VERSION "HINBNNNYYNNNYYNNNNNNNNNNNNYNNNYYYNNYNNNNNN/4//%%/4/'%**4NNN///"

NS_ :

BS_:

BU_: VirtualNMTMaster Master LadderDrive ControlPanel SupportFront SupportRear TTGateway

BO_ 1410 SSDO_002: 8 TTGateway
 SG_ requested_engine_speed_minimum_v m3 : 32|16@1+ (1,0) [0|65535] "" Vector__XXX
 SG_ requested_engine_speed_maximum_v m2 : 32|16@1+ (1,0) [0|65535] "" Vector__XXX
 SG_ requested_engine_speed_value_614 m1 : 32|16@1+ (1,0) [0|65535] "" Vector__XXX
 SG_ requested_engine_speed_number_of m0 : 32|8@1+ (1,0) [0|255] "" Vector__XXX
 SG_ SubIndex_614A m24906M : 24|8@1+ (1,0) [0|3] "" Vector__XXX
 SG_ requested_engine_speed_lowe_0001 m3 : 32|16@1+ (1,0) [0|65535] "" Vector__XXX
 SG_ requested_engine_speed_lowe_0002 m2 : 32|16@1+ (1,0) [0|65535] "" Vector__XXX
 SG_ requested_engine_speed_lowe_0003 m1 : 32|16@1+ (1,0) [0|65535] "" Vector__XXX
 SG_ requested_engine_speed_lowe_0004 m0 : 32|8@1+ (1,0) [0|255] "" Vector__XXX
 SG_ SubIndex_6142 m24898M : 24|8@1+ (1,0) [0|3] "" Vector__XXX
 SG_ requested_engine_speed_uppe_0001 m3 : 32|16@1+ (1,0) [0|65535] "" Vector__XXX
 SG_ requested_engine_speed_uppe_0002 m2 : 32|16@1+ (1,0) [0|65535] "" Vector__XXX
 SG_ requested_engine_speed_uppe_0003 m1 : 32|16@1+ (1,0) [0|65535] "" Vector__XXX
 SG_ requested_engine_speed_uppe_0004 m0 : 32|8@1+ (1,0) [0|255] "" Vector__XXX
 SG_ SubIndex_6140 m24896M : 24|8@1+ (1,0) [0|3] "" Vector__XXX
 SG_ engine_stop_switch_Bit_1_613F_01 m1 : 32|8@1+ (1,0) [0|255] "" Vector__XXX
 SG_ engine_stop_switch_Number_of_ent m0 : 32|8@1+ (1,0) [0|255] "" Vector__XXX
 SG_ SubIndex_613F m24895M : 24|8@1+ (1,0) [0|1] "" Vector__XXX
 SG_ engine_start_switch_Bit_1_613E_0 m1 : 32|8@1+ (1,0) [0|255] "" Vector__XXX
 SG_ engine_start_switch_Number_of_en m0 : 32|8@1+ (1,0) [0|255] "" Vector__XXX
 SG_ SubIndex_613E m24894M : 24|8@1+ (1,0) [0|1] "" Vector__XXX
 SG_ first_clutch_dependent_PTO__0001 m1 : 32|8@1+ (1,0) [0|255] "" Vector__XXX
 SG_ first_clutch_dependent_PTO__0002 m0 : 32|8@1+ (1,0) [0|255] "" Vector__XXX
 SG_ SubIndex_6136 m24886M : 24|8@1+ (1,0) [0|1] "" Vector__XXX
 SG_ first_engine_mounted_PTO_fe_0001 m1 : 32|8@1+ (1,0) [0|255] "" Vector__XXX
 SG_ first_engine_mounted_PTO_fe_0002 m0 : 32|8@1+ (1,0) [0|255] "" Vector__XXX
 SG_ SubIndex_6131 m24881M : 24|8@1+ (1,0) [0|1] "" Vector__XXX
 SG_ engine_speed_minimum_value_range m3 : 32|16@1+ (1,0) [0|65535] "" Vector__XXX
 SG_ engine_speed_maximum_value_range m2 : 32|16@1+ (1,0) [0|65535] "" Vector__XXX
 SG_ EngineSpeed_6113_01 m1 : 32|16@1+ (1,0) [0|65535] "" Vector__XXX
 SG_ NrOfObjects_6113_00 m0 : 32|8@1+ (1,0) [0|255] "" Vector__XXX
 SG_ SubIndex_6113 m24851M : 24|8@1+ (1,0) [0|3] "" Vector__XXX
 SG_ current_gear_minimum_value_range m3 : 32|8@1- (1,0) [-128|127] "" Vector__XXX
 SG_ current_gear_maximum_value_range m2 : 32|8@1- (1,0) [-128|127] "" Vector__XXX
 SG_ CurrentGearValue_610C_01 m1 : 32|8@1- (1,0) [-128|127] "" Vector__XXX
 SG_ NrOfObjects_610C_00 m0 : 32|8@1+ (1,0) [0|255] "" Vector__XXX
 SG_ SubIndex_610C m24844M : 24|8@1+ (1,0) [0|3] "" Vector__XXX
 SG_ wheel_based_vehicle_speed_minimu m3 : 32|16@1+ (1,0) [0|65535] "" Vector__XXX
 SG_ wheel_based_vehicle_speed_maximu m2 : 32|16@1+ (1,0) [0|65535] "" Vector__XXX
 SG_ wheel_based_vehicle_speed_v_0001 m1 : 32|16@1+ (1,0) [0|65535] "" Vector__XXX
 SG_ wheel_based_vehicle_speed_number m0 : 32|8@1+ (1,0) [0|255] "" Vector__XXX
 SG_ SubIndex_6006 m24582M : 24|8@1+ (1,0) [0|3] "" Vector__XXX
 SG_ park_brake_demand_value_minimum_ m3 : 32|8@1+ (1,0) [0|255] "" Vector__XXX
 SG_ park_brake_demand_value_maximum_ m2 : 32|8@1+ (1,0) [0|255] "" Vector__XXX
 SG_ ParkBrakeDemandValue_6000_01 m1 : 32|8@1+ (1,0) [0|255] "" Vector__XXX
 SG_ NrOfObjects_6000_00 m0 : 32|8@1+ (1,0) [0|255] "" Vector__XXX
 SG_ SubIndex_6000 m24576M : 24|8@1+ (1,0) [0|3] "" Vector__XXX
 SG_ NrOfMappedObjects_1A02_00 m0 : 32|8@1+ (1,0) [0|64] "" Vector__XXX
 SG_ SubIndex_1A02 m6658M : 24|8@1+ (1,0) [0|0] "" Vector__XXX
 SG_ NrOfMappedObjects_1A01_00 m0 : 32|8@1+ (1,0) [0|64] "" Vector__XXX
 SG_ SubIndex_1A01 m6657M : 24|8@1+ (1,0) [0|0] "" Vector__XXX
 SG_ mappedObj5_1A00_05 m5 : 32|32@1+ (1,0) [0|4294967295] "" Vector__XXX
 SG_ mappedObj4_1A00_04 m4 : 32|32@1+ (1,0) [0|4294967295] "" Vector__XXX
 SG_ mappedObj3_1A00_03 m3 : 32|32@1+ (1,0) [0|4294967295] "" Vector__XXX
 SG_ mappedObj2_1A00_02 m2 : 32|32@1+ (1,0) [0|4294967295] "" Vector__XXX
 SG_ mappedObj1_1A00_01 m1 : 32|32@1+ (1,0) [0|4294967295] "" Vector__XXX
 SG_ NrOfMappedObjects_1A00_00 m0 : 32|8@1+ (1,0) [0|64] "" Vector__XXX
 SG_ SubIndex_1A00 m6656M : 24|8@1+ (1,0) [0|5] "" Vector__XXX
 SG_ EventTimer_1802_05 m5 : 32|16@1+ (1,0) [0|65535] "" Vector__XXX
 SG_ TransmissionType_1802_02 m2 : 32|8@1+ (1,0) [0|255] "" Vector__XXX
 SG_ COB_ID_1802_01 m1 : 32|32@1+ (1,0) [1|4294967295] "" Vector__XXX
 SG_ NrOfEntries_1802_00 m0 : 32|8@1+ (1,0) [2|5] "" Vector__XXX
 SG_ SubIndex_1802 m6146M : 24|8@1+ (1,0) [0|5] "" Vector__XXX
 SG_ EventTimer_1801_05 m5 : 32|16@1+ (1,0) [0|65535] "" Vector__XXX
 SG_ TransmissionType_1801_02 m2 : 32|8@1+ (1,0) [0|255] "" Vector__XXX
 SG_ COB_ID_1801_01 m1 : 32|32@1+ (1,0) [1|4294967295] "" Vector__XXX
 SG_ NrOfEntries_1801_00 m0 : 32|8@1+ (1,0) [2|5] "" Vector__XXX
 SG_ SubIndex_1801 m6145M : 24|8@1+ (1,0) [0|5] "" Vector__XXX
 SG_ EventTimer_1800_05 m5 : 32|16@1+ (1,0) [0|65535] "" Vector__XXX
 SG_ TransmissionType_1800_02 m2 : 32|8@1+ (1,0) [0|255] "" Vector__XXX
 SG_ COB_ID_1800_01 m1 : 32|32@1+ (1,0) [1|4294967295] "" Vector__XXX
 SG_ NrOfEntries_1800_00 m0 : 32|8@1+ (1,0) [2|5] "" Vector__XXX
 SG_ SubIndex_1800 m6144M : 24|8@1+ (1,0) [0|5] "" Vector__XXX
 SG_ NrOfMappedObjects_1602_00 m0 : 32|8@1+ (1,0) [0|64] "" Vector__XXX
 SG_ SubIndex_1602 m5634M : 24|8@1+ (1,0) [0|0] "" Vector__XXX
 SG_ mappedObj1_1601_01 m1 : 32|32@1+ (1,0) [0|4294967295] "" Vector__XXX
 SG_ NrOfMappedObjects_1601_00 m0 : 32|8@1+ (1,0) [0|64] "" Vector__XXX
 SG_ SubIndex_1601 m5633M : 24|8@1+ (1,0) [0|1] "" Vector__XXX
 SG_ mappedObj5_1600_05 m5 : 32|32@1+ (1,0) [0|4294967295] "" Vector__XXX
 SG_ mappedObj4_1600_04 m4 : 32|32@1+ (1,0) [0|4294967295] "" Vector__XXX
 SG_ mappedObj3_1600_03 m3 : 32|32@1+ (1,0) [0|4294967295] "" Vector__XXX
 SG_ mappedObj2_1600_02 m2 : 32|32@1+ (1,0) [0|4294967295] "" Vector__XXX
 SG_ mappedObj1_1600_01 m1 : 32|32@1+ (1,0) [0|4294967295] "" Vector__XXX
 SG_ NrOfMappedObjects_1600_00 m0 : 32|8@1+ (1,0) [0|64] "" Vector__XXX
 SG_ SubIndex_1600 m5632M : 24|8@1+ (1,0) [0|5] "" Vector__XXX
 SG_ TransmissionType_1402_02 m2 : 32|8@1+ (1,0) [0|255] "" Vector__XXX
 SG_ COB_ID_1402_01 m1 : 32|32@1+ (1,0) [1|4294967295] "" Vector__XXX
 SG_ NrOfEntries_1402_00 m0 : 32|8@1+ (1,0) [2|5] "" Vector__XXX
 SG_ SubIndex_1402 m5122M : 24|8@1+ (1,0) [0|2] "" Vector__XXX
 SG_ TransmissionType_1401_02 m2 : 32|8@1+ (1,0) [0|255] "" Vector__XXX
 SG_ COB_ID_1401_01 m1 : 32|32@1+ (1,0) [1|4294967295] "" Vector__XXX
 SG_ NrOfEntries_1401_00 m0 : 32|8@1+ (1,0) [2|5] "" Vector__XXX
 SG_ SubIndex_1401 m5121M : 24|8@1+ (1,0) [0|2] "" Vector__XXX
 SG_ TransmissionType_1400_02 m2 : 32|8@1+ (1,0) [0|255] "" Vector__XXX
 SG_ COB_ID_1400_01 m1 : 32|32@1+ (1,0) [1|4294967295] "" Vector__XXX
 SG_ NrOfEntries_1400_00 m0 : 32|8@1+ (1,0) [2|5] "" Vector__XXX
 SG_ SubIndex_1400 m5120M : 24|8@1+ (1,0) [0|2] "" Vector__XXX
 SG_ Vendor_Id_1018_01 m1 : 32|32@1+ (1,0) [0|4294967295] "" Vector__XXX
 SG_ NrOfElements_1018_00 m0 : 32|8@1+ (1,0) [1|4] "" Vector__XXX
 SG_ SubIndex_1018 m4120M : 24|8@1+ (1,0) [0|1] "" Vector__XXX
 SG_ Sync_Window_Length_1007 m0 : 32|32@1+ (1,0) [0|4294967295] "" Vector__XXX
 SG_ SubIndex_1007 m4103M : 24|8@1+ (1,0) [0|0] "" Vector__XXX
 SG_ Communication_Cycle_Period_1006 m0 : 32|32@1+ (1,0) [0|4294967295] "" Vector__XXX
 SG_ SubIndex_1006 m4102M : 24|8@1+ (1,0) [0|0] "" Vector__XXX
 SG_ COB_ID_SYNC_1005 m0 : 32|32@1+ (1,0) [1|4294967295] "" Vector__XXX
 SG_ SubIndex_1005 m4101M : 24|8@1+ (1,0) [0|0] "" Vector__XXX
 SG_ ErrorRegister_1001 m0 : 32|8@1+ (1,0) [0|255] "" Vector__XXX
 SG_ SubIndex_1001 m4097M : 24|8@1+ (1,0) [0|0] "" Vector__XXX
 SG_ Device_Type_1000 m0 : 32|32@1+ (1,0) [0|4294967295] "" Vector__XXX
 SG_ SubIndex_1000 m4096M : 24|8@1+ (1,0) [0|0] "" Vector__XXX
 SG_ Index m1M : 8|16@1+ (1,0) [4096|24906] "" Vector__XXX
 SG_ TransferType m1M : 1|1@1+ (1,0) [0|1] "" Vector__XXX
 SG_ NotUsedBytes m1 : 2|2@1+ (1,0) [0|3] "" Vector__XXX
 SG_ SizeIndicator m1 : 0|1@1+ (1,0) [0|1] "" Vector__XXX
 SG_ SCS M : 5|3@1+ (1,0) [0|6] "" Vector__XXX

BO_ 1538 CSDO_002: 8 Vector__XXX
 SG_ requested_engine_speed_mini_0000 m3 : 32|16@1+ (1,0) [0|65535] ""  TTGateway
 SG_ requested_engine_speed_maxi_0000 m2 : 32|16@1+ (1,0) [0|65535] ""  TTGateway
 SG_ requested_engine_speed_valu_0001 m1 : 32|16@1+ (1,0) [0|65535] ""  TTGateway
 SG_ requested_engine_speed_numb_0000 m0 : 32|8@1+ (1,0) [0|255] ""  TTGateway
 SG_ SubIndex_614A m24906M : 24|8@1+ (1,0) [0|3] ""  TTGateway
 SG_ requested_engine_speed_lowe_0005 m3 : 32|16@1+ (1,0) [0|65535] ""  TTGateway
 SG_ requested_engine_speed_lowe_0006 m2 : 32|16@1+ (1,0) [0|65535] ""  TTGateway
 SG_ requested_engine_speed_lowe_0007 m1 : 32|16@1+ (1,0) [0|65535] ""  TTGateway
 SG_ requested_engine_speed_lowe_0008 m0 : 32|8@1+ (1,0) [0|255] ""  TTGateway
 SG_ SubIndex_6142 m24898M : 24|8@1+ (1,0) [0|3] ""  TTGateway
 SG_ requested_engine_speed_uppe_0005 m3 : 32|16@1+ (1,0) [0|65535] ""  TTGateway
 SG_ requested_engine_speed_uppe_0006 m2 : 32|16@1+ (1,0) [0|65535] ""  TTGateway
 SG_ requested_engine_speed_uppe_0007 m1 : 32|16@1+ (1,0) [0|65535] ""  TTGateway
 SG_ requested_engine_speed_uppe_0008 m0 : 32|8@1+ (1,0) [0|255] ""  TTGateway
 SG_ SubIndex_6140 m24896M : 24|8@1+ (1,0) [0|3] ""  TTGateway
 SG_ engine_stop_switch_Bit_1_613F_01 m1 : 32|8@1+ (1,0) [0|255] ""  TTGateway
 SG_ engine_stop_switch_Number_o_0000 m0 : 32|8@1+ (1,0) [0|255] ""  TTGateway
 SG_ SubIndex_613F m24895M : 24|8@1+ (1,0) [0|1] ""  TTGateway
 SG_ engine_start_switch_Bit_1_6_0000 m1 : 32|8@1+ (1,0) [0|255] ""  TTGateway
 SG_ engine_start_switch_Number__0000 m0 : 32|8@1+ (1,0) [0|255] ""  TTGateway
 SG_ SubIndex_613E m24894M : 24|8@1+ (1,0) [0|1] ""  TTGateway
 SG_ first_clutch_dependent_PTO__0003 m1 : 32|8@1+ (1,0) [0|255] ""  TTGateway
 SG_ first_clutch_dependent_PTO__0004 m0 : 32|8@1+ (1,0) [0|255] ""  TTGateway
 SG_ SubIndex_6136 m24886M : 24|8@1+ (1,0) [0|1] ""  TTGateway
 SG_ first_engine_mounted_PTO_fe_0003 m1 : 32|8@1+ (1,0) [0|255] ""  TTGateway
 SG_ first_engine_mounted_PTO_fe_0004 m0 : 32|8@1+ (1,0) [0|255] ""  TTGateway
 SG_ SubIndex_6131 m24881M : 24|8@1+ (1,0) [0|1] ""  TTGateway
 SG_ engine_speed_minimum_value__0000 m3 : 32|16@1+ (1,0) [0|65535] ""  TTGateway
 SG_ engine_speed_maximum_value__0000 m2 : 32|16@1+ (1,0) [0|65535] ""  TTGateway
 SG_ EngineSpeed_6113_01 m1 : 32|16@1+ (1,0) [0|65535] ""  TTGateway
 SG_ NrOfObjects_6113_00 m0 : 32|8@1+ (1,0) [0|255] ""  TTGateway
 SG_ SubIndex_6113 m24851M : 24|8@1+ (1,0) [0|3] ""  TTGateway
 SG_ current_gear_minimum_value__0000 m3 : 32|8@1- (1,0) [-128|127] ""  TTGateway
 SG_ current_gear_maximum_value__0000 m2 : 32|8@1- (1,0) [-128|127] ""  TTGateway
 SG_ CurrentGearValue_610C_01 m1 : 32|8@1- (1,0) [-128|127] ""  TTGateway
 SG_ NrOfObjects_610C_00 m0 : 32|8@1+ (1,0) [0|255] ""  TTGateway
 SG_ SubIndex_610C m24844M : 24|8@1+ (1,0) [0|3] ""  TTGateway
 SG_ wheel_based_vehicle_speed_m_0000 m3 : 32|16@1+ (1,0) [0|65535] ""  TTGateway
 SG_ wheel_based_vehicle_speed_m_0001 m2 : 32|16@1+ (1,0) [0|65535] ""  TTGateway
 SG_ wheel_based_vehicle_speed_v_0002 m1 : 32|16@1+ (1,0) [0|65535] ""  TTGateway
 SG_ wheel_based_vehicle_speed_n_0000 m0 : 32|8@1+ (1,0) [0|255] ""  TTGateway
 SG_ SubIndex_6006 m24582M : 24|8@1+ (1,0) [0|3] ""  TTGateway
 SG_ park_brake_demand_value_min_0000 m3 : 32|8@1+ (1,0) [0|255] ""  TTGateway
 SG_ park_brake_demand_value_max_0000 m2 : 32|8@1+ (1,0) [0|255] ""  TTGateway
 SG_ ParkBrakeDemandValue_6000_01 m1 : 32|8@1+ (1,0) [0|255] ""  TTGateway
 SG_ NrOfObjects_6000_00 m0 : 32|8@1+ (1,0) [0|255] ""  TTGateway
 SG_ SubIndex_6000 m24576M : 24|8@1+ (1,0) [0|3] ""  TTGateway
 SG_ NrOfMappedObjects_1A02_00 m0 : 32|8@1+ (1,0) [0|64] ""  TTGateway
 SG_ SubIndex_1A02 m6658M : 24|8@1+ (1,0) [0|0] ""  TTGateway
 SG_ NrOfMappedObjects_1A01_00 m0 : 32|8@1+ (1,0) [0|64] ""  TTGateway
 SG_ SubIndex_1A01 m6657M : 24|8@1+ (1,0) [0|0] ""  TTGateway
 SG_ mappedObj5_1A00_05 m5 : 32|32@1+ (1,0) [0|4294967295] ""  TTGateway
 SG_ mappedObj4_1A00_04 m4 : 32|32@1+ (1,0) [0|4294967295] ""  TTGateway
 SG_ mappedObj3_1A00_03 m3 : 32|32@1+ (1,0) [0|4294967295] ""  TTGateway
 SG_ mappedObj2_1A00_02 m2 : 32|32@1+ (1,0) [0|4294967295] ""  TTGateway
 SG_ mappedObj1_1A00_01 m1 : 32|32@1+ (1,0) [0|4294967295] ""  TTGateway
 SG_ NrOfMappedObjects_1A00_00 m0 : 32|8@1+ (1,0) [0|64] ""  TTGateway
 SG_ SubIndex_1A00 m6656M : 24|8@1+ (1,0) [0|5] ""  TTGateway
 SG_ EventTimer_1802_05 m5 : 32|16@1+ (1,0) [0|65535] ""  TTGateway
 SG_ TransmissionType_1802_02 m2 : 32|8@1+ (1,0) [0|255] ""  TTGateway
 SG_ COB_ID_1802_01 m1 : 32|32@1+ (1,0) [1|4294967295] ""  TTGateway
 SG_ NrOfEntries_1802_00 m0 : 32|8@1+ (1,0) [2|5] ""  TTGateway
 SG_ SubIndex_1802 m6146M : 24|8@1+ (1,0) [0|5] ""  TTGateway
 SG_ EventTimer_1801_05 m5 : 32|16@1+ (1,0) [0|65535] ""  TTGateway
 SG_ TransmissionType_1801_02 m2 : 32|8@1+ (1,0) [0|255] ""  TTGateway
 SG_ COB_ID_1801_01 m1 : 32|32@1+ (1,0) [1|4294967295] ""  TTGateway
 SG_ NrOfEntries_1801_00 m0 : 32|8@1+ (1,0) [2|5] ""  TTGateway
 SG_ SubIndex_1801 m6145M : 24|8@1+ (1,0) [0|5] ""  TTGateway
 SG_ EventTimer_1800_05 m5 : 32|16@1+ (1,0) [0|65535] ""  TTGateway
 SG_ TransmissionType_1800_02 m2 : 32|8@1+ (1,0) [0|255] ""  TTGateway
 SG_ COB_ID_1800_01 m1 : 32|32@1+ (1,0) [1|4294967295] ""  TTGateway
 SG_ NrOfEntries_1800_00 m0 : 32|8@1+ (1,0) [2|5] ""  TTGateway
 SG_ SubIndex_1800 m6144M : 24|8@1+ (1,0) [0|5] ""  TTGateway
 SG_ NrOfMappedObjects_1602_00 m0 : 32|8@1+ (1,0) [0|64] ""  TTGateway
 SG_ SubIndex_1602 m5634M : 24|8@1+ (1,0) [0|0] ""  TTGateway
 SG_ mappedObj1_1601_01 m1 : 32|32@1+ (1,0) [0|4294967295] ""  TTGateway
 SG_ NrOfMappedObjects_1601_00 m0 : 32|8@1+ (1,0) [0|64] ""  TTGateway
 SG_ SubIndex_1601 m5633M : 24|8@1+ (1,0) [0|1] ""  TTGateway
 SG_ mappedObj5_1600_05 m5 : 32|32@1+ (1,0) [0|4294967295] ""  TTGateway
 SG_ mappedObj4_1600_04 m4 : 32|32@1+ (1,0) [0|4294967295] ""  TTGateway
 SG_ mappedObj3_1600_03 m3 : 32|32@1+ (1,0) [0|4294967295] ""  TTGateway
 SG_ mappedObj2_1600_02 m2 : 32|32@1+ (1,0) [0|4294967295] ""  TTGateway
 SG_ mappedObj1_1600_01 m1 : 32|32@1+ (1,0) [0|4294967295] ""  TTGateway
 SG_ NrOfMappedObjects_1600_00 m0 : 32|8@1+ (1,0) [0|64] ""  TTGateway
 SG_ SubIndex_1600 m5632M : 24|8@1+ (1,0) [0|5] ""  TTGateway
 SG_ TransmissionType_1402_02 m2 : 32|8@1+ (1,0) [0|255] ""  TTGateway
 SG_ COB_ID_1402_01 m1 : 32|32@1+ (1,0) [1|4294967295] ""  TTGateway
 SG_ NrOfEntries_1402_00 m0 : 32|8@1+ (1,0) [2|5] ""  TTGateway
 SG_ SubIndex_1402 m5122M : 24|8@1+ (1,0) [0|2] ""  TTGateway
 SG_ TransmissionType_1401_02 m2 : 32|8@1+ (1,0) [0|255] ""  TTGateway
 SG_ COB_ID_1401_01 m1 : 32|32@1+ (1,0) [1|4294967295] ""  TTGateway
 SG_ NrOfEntries_1401_00 m0 : 32|8@1+ (1,0) [2|5] ""  TTGateway
 SG_ SubIndex_1401 m5121M : 24|8@1+ (1,0) [0|2] ""  TTGateway
 SG_ TransmissionType_1400_02 m2 : 32|8@1+ (1,0) [0|255] ""  TTGateway
 SG_ COB_ID_1400_01 m1 : 32|32@1+ (1,0) [1|4294967295] ""  TTGateway
 SG_ NrOfEntries_1400_00 m0 : 32|8@1+ (1,0) [2|5] ""  TTGateway
 SG_ SubIndex_1400 m5120M : 24|8@1+ (1,0) [0|2] ""  TTGateway
 SG_ Vendor_Id_1018_01 m1 : 32|32@1+ (1,0) [0|4294967295] ""  TTGateway
 SG_ NrOfElements_1018_00 m0 : 32|8@1+ (1,0) [1|4] ""  TTGateway
 SG_ SubIndex_1018 m4120M : 24|8@1+ (1,0) [0|1] ""  TTGateway
 SG_ Sync_Window_Length_1007 m0 : 32|32@1+ (1,0) [0|4294967295] ""  TTGateway
 SG_ SubIndex_1007 m4103M : 24|8@1+ (1,0) [0|0] ""  TTGateway
 SG_ Communication_Cycle_Period_1006 m0 : 32|32@1+ (1,0) [0|4294967295] ""  TTGateway
 SG_ SubIndex_1006 m4102M : 24|8@1+ (1,0) [0|0] ""  TTGateway
 SG_ COB_ID_SYNC_1005 m0 : 32|32@1+ (1,0) [1|4294967295] ""  TTGateway
 SG_ SubIndex_1005 m4101M : 24|8@1+ (1,0) [0|0] ""  TTGateway
 SG_ ErrorRegister_1001 m0 : 32|8@1+ (1,0) [0|255] ""  TTGateway
 SG_ SubIndex_1001 m4097M : 24|8@1+ (1,0) [0|0] ""  TTGateway
 SG_ Device_Type_1000 m0 : 32|32@1+ (1,0) [0|4294967295] ""  TTGateway
 SG_ SubIndex_1000 m4096M : 24|8@1+ (1,0) [0|0] ""  TTGateway
 SG_ Index m1M : 8|16@1+ (1,0) [4096|24906] ""  TTGateway
 SG_ TransferType m1M : 1|1@1+ (1,0) [0|1] ""  TTGateway
 SG_ NotUsedBytes m1 : 2|2@1+ (1,0) [0|3] ""  TTGateway
 SG_ SizeIndicator m1 : 0|1@1+ (1,0) [0|1] ""  TTGateway
 SG_ CCS M : 5|3@1+ (1,0) [0|6] ""  TTGateway

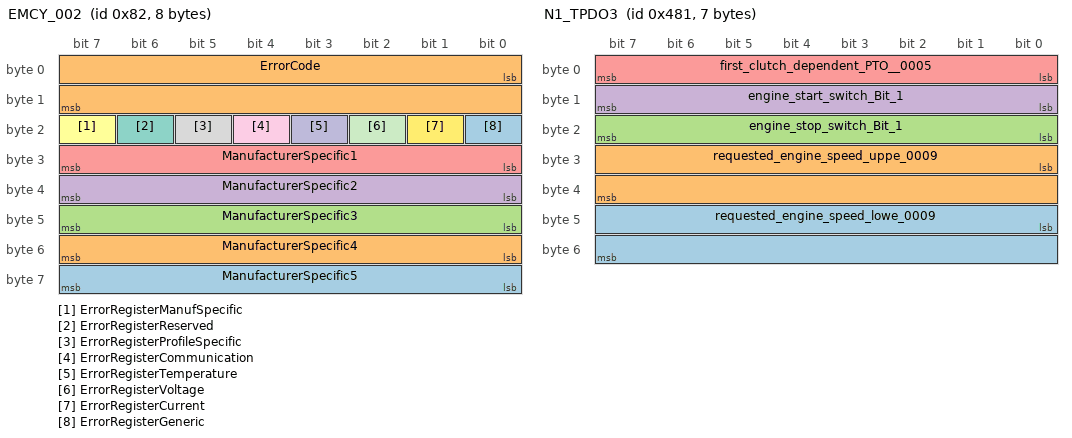
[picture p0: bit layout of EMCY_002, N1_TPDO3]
BO_ 130 EMCY_002: 8 TTGateway
 SG_ ManufacturerSpecific5 : 56|8@1+ (1,0) [0|0] "" Vector__XXX
 SG_ ManufacturerSpecific4 : 48|8@1+ (1,0) [0|0] "" Vector__XXX
 SG_ ManufacturerSpecific3 : 40|8@1+ (1,0) [0|0] "" Vector__XXX
 SG_ ManufacturerSpecific2 : 32|8@1+ (1,0) [0|0] "" Vector__XXX
 SG_ ManufacturerSpecific1 : 24|8@1+ (1,0) [0|0] "" Vector__XXX
 SG_ ErrorRegisterManufSpecific : 23|1@1+ (1,0) [0|0] "" Vector__XXX
 SG_ ErrorRegisterReserved : 22|1@1+ (1,0) [0|0] "" Vector__XXX
 SG_ ErrorRegisterProfileSpecific : 21|1@1+ (1,0) [0|0] "" Vector__XXX
 SG_ ErrorRegisterCommunication : 20|1@1+ (1,0) [0|0] "" Vector__XXX
 SG_ ErrorRegisterTemperature : 19|1@1+ (1,0) [0|0] "" Vector__XXX
 SG_ ErrorRegisterVoltage : 18|1@1+ (1,0) [0|0] "" Vector__XXX
 SG_ ErrorRegisterCurrent : 17|1@1+ (1,0) [0|0] "" Vector__XXX
 SG_ ErrorRegisterGeneric : 16|1@1+ (1,0) [0|0] "" Vector__XXX
 SG_ ErrorCode : 0|16@1+ (1,0) [0|0] "" Vector__XXX

BO_ 127 RED_IndicateActiveCANLine: 0 Vector__XXX

BO_ 118 FM_ForceReset: 0 Vector__XXX

BO_ 117 FM_ReqMasterCapable: 0 Vector__XXX

BO_ 116 FM_RspMasterCapable: 0 Vector__XXX

BO_ 115 FM_ReqPrioLevel: 0 Vector__XXX

BO_ 114 FM_TriggerTimeSlot: 0 Vector__XXX

BO_ 113 FM_MasterPrioLevel: 2 Vector__XXX
 SG_ FM_NodeID : 8|8@1+ (1,0) [0|0] "" Vector__XXX
 SG_ FM_PrioLevel : 0|8@1+ (1,0) [0|0] "" Vector__XXX

BO_ 256 TIME: 6 Vector__XXX
 SG_ days : 32|16@1+ (1,0) [0|65535] "days" Vector__XXX
 SG_ ms : 0|28@1+ (1,0) [0|86399999] "ms" Vector__XXX

BO_ 128 SYNC: 0 Vector__XXX

BO_ 0 NMTZeroMsg: 2 VirtualNMTMaster
 SG_ Node_ID : 8|8@1+ (1,0) [0|0] "" Vector__XXX
 SG_ CS : 0|8@1+ (1,0) [0|0] "" Vector__XXX

BO_ 1760 DynSDOReq: 0 Vector__XXX

BO_ 2021 LSS_M: 8 Vector__XXX
 SG_ LSS_ID_Number m81 : 8|32@1+ (1,0) [0|0] "" Vector__XXX
 SG_ LSS_BitCheck m81 : 40|8@1+ (1,0) [0|0] "" Vector__XXX
 SG_ LSS_Sub m81 : 48|8@1+ (1,0) [0|0] "" Vector__XXX
 SG_ LSS_Next m81 : 56|8@1+ (1,0) [0|0] "" Vector__XXX
 SG_ LSS_SwitchDelay m21 : 8|16@1+ (1,0) [0|0] "" Vector__XXX
 SG_ LSS_CfgNodeID m17 : 8|8@1+ (1,0) [0|0] "" Vector__XXX
 SG_ LSS_IdentSerialHigh m75 : 8|32@1+ (1,0) [0|0] "" Vector__XXX
 SG_ LSS_IdentSerialLow m74 : 8|32@1+ (1,0) [0|0] "" Vector__XXX
 SG_ LSS_IdentRevisionHigh m73 : 8|32@1+ (1,0) [0|0] "" Vector__XXX
 SG_ LSS_IdentRevisionLow m72 : 8|32@1+ (1,0) [0|0] "" Vector__XXX
 SG_ LSS_IdentProductCode m71 : 8|32@1+ (1,0) [0|0] "" Vector__XXX
 SG_ LSS_IdentVendorId m70 : 8|32@1+ (1,0) [0|0] "" Vector__XXX
 SG_ LSS_TableIndex m19 : 16|8@1+ (1,0) [0|0] "" Vector__XXX
 SG_ LSS_TableSelector m19 : 8|8@1+ (1,0) [0|0] "" Vector__XXX
 SG_ LSS_SwitchSerial m67 : 8|32@1+ (1,0) [0|0] "" Vector__XXX
 SG_ LSS_SwitchRevision m66 : 8|32@1+ (1,0) [0|0] "" Vector__XXX
 SG_ LSS_SwitchProductCode m65 : 8|32@1+ (1,0) [0|0] "" Vector__XXX
 SG_ LSS_SwitchVendorId m64 : 8|32@1+ (1,0) [0|0] "" Vector__XXX
 SG_ LSS_Mode m4 : 8|8@1+ (1,0) [0|0] "" Vector__XXX
 SG_ LSS_M_CS M : 0|8@1+ (1,0) [0|0] "" Vector__XXX

BO_ 2020 LSS_S: 8 Vector__XXX
 SG_ LSS_NodeId m94 : 8|8@1+ (1,0) [0|0] "" Vector__XXX
 SG_ LSS_Serial m93 : 8|32@1+ (1,0) [0|0] "" Vector__XXX
 SG_ LSS_Revision m92 : 8|32@1+ (1,0) [0|0] "" Vector__XXX
 SG_ LSS_ProductId m91 : 8|32@1+ (1,0) [0|0] "" Vector__XXX
 SG_ LSS_VendorId m90 : 8|32@1+ (1,0) [0|0] "" Vector__XXX
 SG_ LSS_StoreCfg_SpecErr m23 : 16|8@1+ (1,0) [0|0] "" Vector__XXX
 SG_ LSS_StoreCfg_ErrCode m23 : 8|8@1+ (1,0) [0|0] "" Vector__XXX
 SG_ LSS_CfgBitTim_SpecErr m19 : 16|8@1+ (1,0) [0|0] "" Vector__XXX
 SG_ LSS_CfgBitTim_ErrCode m19 : 8|8@1+ (1,0) [0|0] "" Vector__XXX
 SG_ LSS_CfgNodeID_SpecErr m17 : 16|8@1+ (1,0) [0|0] "" Vector__XXX
 SG_ LSS_CfgNodeID_ErrCode m17 : 8|8@1+ (1,0) [0|0] "" Vector__XXX
 SG_ LSS_S_CS M : 0|8@1+ (1,0) [0|0] "" Vector__XXX

BO_ 1 GFC: 0 Vector__XXX

BO_ 661 N1_TPDO4: 2 Master
 SG_ requested_engine_speed_value : 0|16@1+ (1,0) [0|0] ""  TTGateway

BO_ 1153 N1_TPDO3: 7 Master
 SG_ requested_engine_speed_lowe_0009 : 40|16@1+ (1,0) [0|0] ""  TTGateway
 SG_ requested_engine_speed_uppe_0009 : 24|16@1+ (1,0) [0|0] ""  TTGateway
 SG_ engine_stop_switch_Bit_1 : 16|8@1+ (1,0) [0|0] ""  TTGateway
 SG_ engine_start_switch_Bit_1 : 8|8@1+ (1,0) [0|0] ""  TTGateway
 SG_ first_clutch_dependent_PTO__0005 : 0|8@1+ (1,0) [0|0] ""  TTGateway

BO_ 897 N1_TPDO2: 4 Master
 SG_ controlword_sup_rear : 16|16@1+ (1,0) [0|0] ""  SupportRear
 SG_ vl_target_velocity_sup_rear : 0|16@1- (1,0) [0|0] ""  SupportRear

BO_ 641 N1_TPDO1: 4 Master
 SG_ controlword_sup_front : 16|16@1+ (1,0) [0|0] ""  SupportFront
 SG_ vl_target_velocity_sup_front : 0|16@1- (1,0) [0|0] ""  SupportFront

BO_ 385 N1_TPDO0: 4 Master
 SG_ controlword_ladder : 16|16@1+ (1,0) [0|0] ""  LadderDrive
 SG_ vl_target_velocity_ladder : 0|16@1- (1,0) [0|0] ""  LadderDrive

BO_ 769 N11_TPDO0: 4 LadderDrive
 SG_ vl_velocity_demand : 16|16@1- (1,0) [0|0] ""  Master
 SG_ statusword : 0|16@1+ (1,0) [0|0] ""  Master

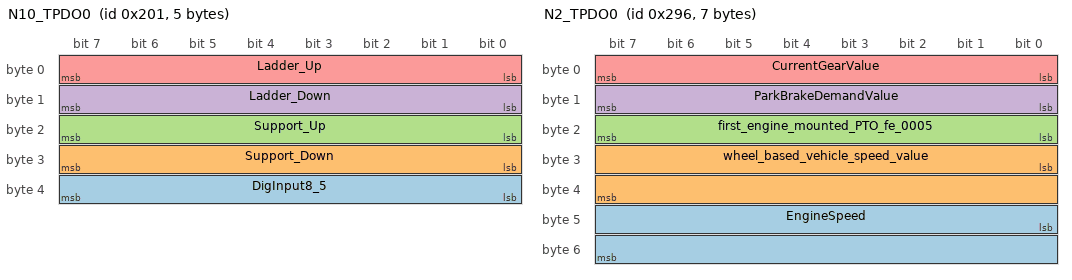
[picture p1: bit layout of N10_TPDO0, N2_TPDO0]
BO_ 513 N10_TPDO0: 5 ControlPanel
 SG_ DigInput8_5 : 32|8@1+ (1,0) [0|0] ""  Master
 SG_ Support_Down : 24|8@1+ (1,0) [0|0] ""  Master
 SG_ Support_Up : 16|8@1+ (1,0) [0|0] ""  Master
 SG_ Ladder_Down : 8|8@1+ (1,0) [0|0] ""  Master
 SG_ Ladder_Up : 0|8@1+ (1,0) [0|0] ""  Master

BO_ 1025 N12_TPDO0: 4 SupportFront
 SG_ vl_velocity_demand : 16|16@1- (1,0) [0|0] ""  Master
 SG_ statusword : 0|16@1+ (1,0) [0|0] ""  Master

BO_ 1281 N13_TPDO0: 4 SupportRear
 SG_ vl_velocity_demand : 16|16@1- (1,0) [0|0] ""  Master
 SG_ statusword : 0|16@1+ (1,0) [0|0] ""  Master

BO_ 662 N2_TPDO0: 7 TTGateway
 SG_ EngineSpeed : 40|16@1+ (1,0) [0|0] ""  Master
 SG_ wheel_based_vehicle_speed_value : 24|16@1+ (1,0) [0|0] ""  Master
 SG_ first_engine_mounted_PTO_fe_0005 : 16|8@1+ (1,0) [0|0] ""  Master
 SG_ ParkBrakeDemandValue : 8|8@1+ (1,0) [0|0] ""  Master
 SG_ CurrentGearValue : 0|8@1- (1,0) [0|0] ""  Master

BA_DEF_ BO_  "GenMsgSendType" ENUM  "Cyclic","SendType1","SendType2","SendType3","SendType4","SendType5","SendType6","SendType7","SendType8","SendType9";
BA_DEF_ BO_  "GenMsgCycleTime" INT 0 0;
BA_DEF_ SG_  "GenSigStartValue" INT 0 0;
BA_DEF_ BO_  "CO_MsgCategory" INT 0 0;
BA_DEF_ SG_  "SystemSignalLongSymbol" STRING ;
BA_DEF_DEF_  "GenMsgSendType" "";
BA_DEF_DEF_  "GenMsgCycleTime" 0;
BA_DEF_DEF_  "GenSigStartValue" 0;
BA_DEF_DEF_  "CO_MsgCategory" 0;
BA_DEF_DEF_  "SystemSignalLongSymbol" "";
BA_ "CO_MsgCategory" BO_ 1410 410;
BA_ "CO_MsgCategory" BO_ 1538 405;
BA_ "CO_MsgCategory" BO_ 130 205;
BA_ "CO_MsgCategory" BO_ 256 115;
BA_ "CO_MsgCategory" BO_ 128 110;
BA_ "CO_MsgCategory" BO_ 0 105;
BA_ "CO_MsgCategory" BO_ 2021 610;
BA_ "CO_MsgCategory" BO_ 2020 605;
BA_ "CO_MsgCategory" BO_ 1 705;
BA_ "CO_MsgCategory" BO_ 661 345;
BA_ "CO_MsgCategory" BO_ 1153 335;
BA_ "CO_MsgCategory" BO_ 897 325;
BA_ "CO_MsgCategory" BO_ 641 315;
BA_ "CO_MsgCategory" BO_ 385 305;
BA_ "CO_MsgCategory" BO_ 769 305;
BA_ "CO_MsgCategory" BO_ 513 305;
BA_ "CO_MsgCategory" BO_ 1025 305;
BA_ "CO_MsgCategory" BO_ 1281 305;
BA_ "CO_MsgCategory" BO_ 662 305;
BA_ "SystemSignalLongSymbol" SG_ 1410 requested_engine_speed_minimum_v "requested_engine_speed_minimum_value_range_614A_03";
BA_ "GenSigStartValue" SG_ 1410 requested_engine_speed_maximum_v 64255;
BA_ "SystemSignalLongSymbol" SG_ 1410 requested_engine_speed_maximum_v "requested_engine_speed_maximum_value_range_614A_02";
BA_ "SystemSignalLongSymbol" SG_ 1410 requested_engine_speed_value_614 "requested_engine_speed_value_614A_01";
BA_ "GenSigStartValue" SG_ 1410 requested_engine_speed_number_of 3;
BA_ "SystemSignalLongSymbol" SG_ 1410 requested_engine_speed_number_of "requested_engine_speed_number_of_entries_614A_00";
BA_ "SystemSignalLongSymbol" SG_ 1410 requested_engine_speed_lowe_0001 "requested_engine_speed_lower_limit_minimum_value_range_6142_03";
BA_ "GenSigStartValue" SG_ 1410 requested_engine_speed_lowe_0002 64255;
BA_ "SystemSignalLongSymbol" SG_ 1410 requested_engine_speed_lowe_0002 "requested_engine_speed_lower_limit_maximum_value_range_6142_02";
BA_ "GenSigStartValue" SG_ 1410 requested_engine_speed_lowe_0003 65535;
BA_ "SystemSignalLongSymbol" SG_ 1410 requested_engine_speed_lowe_0003 "requested_engine_speed_lower_limit_value_6142_01";
BA_ "GenSigStartValue" SG_ 1410 requested_engine_speed_lowe_0004 3;
BA_ "SystemSignalLongSymbol" SG_ 1410 requested_engine_speed_lowe_0004 "requested_engine_speed_lower_limit_number_of_entries_6142_00";
BA_ "SystemSignalLongSymbol" SG_ 1410 requested_engine_speed_uppe_0001 "requested_engine_speed_upper_limit_minimum_value_range_6140_03";
BA_ "GenSigStartValue" SG_ 1410 requested_engine_speed_uppe_0002 64255;
BA_ "SystemSignalLongSymbol" SG_ 1410 requested_engine_speed_uppe_0002 "requested_engine_speed_upper_limit_maximum_value_range_6140_02";
BA_ "GenSigStartValue" SG_ 1410 requested_engine_speed_uppe_0003 65535;
BA_ "SystemSignalLongSymbol" SG_ 1410 requested_engine_speed_uppe_0003 "requested_engine_speed_upper_limit_value_6140_01";
BA_ "GenSigStartValue" SG_ 1410 requested_engine_speed_uppe_0004 3;
BA_ "SystemSignalLongSymbol" SG_ 1410 requested_engine_speed_uppe_0004 "requested_engine_speed_upper_limit_number_of_entries_6140_00";
BA_ "GenSigStartValue" SG_ 1410 engine_stop_switch_Bit_1_613F_01 1;
BA_ "GenSigStartValue" SG_ 1410 engine_stop_switch_Number_of_ent 1;
BA_ "SystemSignalLongSymbol" SG_ 1410 engine_stop_switch_Number_of_ent "engine_stop_switch_Number_of_entries_613F_00";
BA_ "GenSigStartValue" SG_ 1410 engine_start_switch_Bit_1_613E_0 1;
BA_ "SystemSignalLongSymbol" SG_ 1410 engine_start_switch_Bit_1_613E_0 "engine_start_switch_Bit_1_613E_01";
BA_ "GenSigStartValue" SG_ 1410 engine_start_switch_Number_of_en 1;
BA_ "SystemSignalLongSymbol" SG_ 1410 engine_start_switch_Number_of_en "engine_start_switch_Number_of_entries_613E_00";
BA_ "SystemSignalLongSymbol" SG_ 1410 first_clutch_dependent_PTO__0001 "first_clutch_dependent_PTO_switch_Bit_1_6136_01";
BA_ "GenSigStartValue" SG_ 1410 first_clutch_dependent_PTO__0002 1;
BA_ "SystemSignalLongSymbol" SG_ 1410 first_clutch_dependent_PTO__0002 "first_clutch_dependent_PTO_switch_Number_of_entries_6136_00";
BA_ "SystemSignalLongSymbol" SG_ 1410 first_engine_mounted_PTO_fe_0001 "first_engine_mounted_PTO_feedback_Bit_1_6131_01";
BA_ "GenSigStartValue" SG_ 1410 first_engine_mounted_PTO_fe_0002 1;
BA_ "SystemSignalLongSymbol" SG_ 1410 first_engine_mounted_PTO_fe_0002 "first_engine_mounted_PTO_feedback_Number_of_entries_6131_00";
BA_ "SystemSignalLongSymbol" SG_ 1410 engine_speed_minimum_value_range "engine_speed_minimum_value_range_6113_03";
BA_ "GenSigStartValue" SG_ 1410 engine_speed_maximum_value_range 64255;
BA_ "SystemSignalLongSymbol" SG_ 1410 engine_speed_maximum_value_range "engine_speed_maximum_value_range_6113_02";
BA_ "GenSigStartValue" SG_ 1410 EngineSpeed_6113_01 65535;
BA_ "GenSigStartValue" SG_ 1410 NrOfObjects_6113_00 3;
BA_ "GenSigStartValue" SG_ 1410 current_gear_minimum_value_range 4294967171;
BA_ "SystemSignalLongSymbol" SG_ 1410 current_gear_minimum_value_range "current_gear_minimum_value_range_610C_03";
BA_ "GenSigStartValue" SG_ 1410 current_gear_maximum_value_range 125;
BA_ "SystemSignalLongSymbol" SG_ 1410 current_gear_maximum_value_range "current_gear_maximum_value_range_610C_02";
BA_ "GenSigStartValue" SG_ 1410 NrOfObjects_610C_00 3;
BA_ "SystemSignalLongSymbol" SG_ 1410 wheel_based_vehicle_speed_minimu "wheel_based_vehicle_speed_minimum_value_range_6006_03";
BA_ "GenSigStartValue" SG_ 1410 wheel_based_vehicle_speed_maximu 64000;
BA_ "SystemSignalLongSymbol" SG_ 1410 wheel_based_vehicle_speed_maximu "wheel_based_vehicle_speed_maximum_value_range_6006_02";
BA_ "GenSigStartValue" SG_ 1410 wheel_based_vehicle_speed_v_0001 65535;
BA_ "SystemSignalLongSymbol" SG_ 1410 wheel_based_vehicle_speed_v_0001 "wheel_based_vehicle_speed_value_6006_01";
BA_ "GenSigStartValue" SG_ 1410 wheel_based_vehicle_speed_number 3;
BA_ "SystemSignalLongSymbol" SG_ 1410 wheel_based_vehicle_speed_number "wheel_based_vehicle_speed_number_of_entries_6006_00";
BA_ "SystemSignalLongSymbol" SG_ 1410 park_brake_demand_value_minimum_ "park_brake_demand_value_minimum_value_range_6000_03";
BA_ "GenSigStartValue" SG_ 1410 park_brake_demand_value_maximum_ 250;
BA_ "SystemSignalLongSymbol" SG_ 1410 park_brake_demand_value_maximum_ "park_brake_demand_value_maximum_value_range_6000_02";
BA_ "GenSigStartValue" SG_ 1410 NrOfObjects_6000_00 3;
BA_ "GenSigStartValue" SG_ 1410 mappedObj5_1A00_05 1628635408;
BA_ "GenSigStartValue" SG_ 1410 mappedObj4_1A00_04 1611006224;
BA_ "GenSigStartValue" SG_ 1410 mappedObj3_1A00_03 1630601480;
BA_ "GenSigStartValue" SG_ 1410 mappedObj2_1A00_02 1610613000;
BA_ "GenSigStartValue" SG_ 1410 mappedObj1_1A00_01 1628176648;
BA_ "GenSigStartValue" SG_ 1410 NrOfMappedObjects_1A00_00 5;
BA_ "GenSigStartValue" SG_ 1410 TransmissionType_1802_02 255;
BA_ "GenSigStartValue" SG_ 1410 COB_ID_1802_01 2147484546;
BA_ "GenSigStartValue" SG_ 1410 NrOfEntries_1802_00 5;
BA_ "GenSigStartValue" SG_ 1410 TransmissionType_1801_02 255;
BA_ "GenSigStartValue" SG_ 1410 COB_ID_1801_01 2147484290;
BA_ "GenSigStartValue" SG_ 1410 NrOfEntries_1801_00 5;
BA_ "GenSigStartValue" SG_ 1410 TransmissionType_1800_02 255;
BA_ "GenSigStartValue" SG_ 1410 COB_ID_1800_01 662;
BA_ "GenSigStartValue" SG_ 1410 NrOfEntries_1800_00 5;
BA_ "GenSigStartValue" SG_ 1410 mappedObj1_1601_01 1632239888;
BA_ "GenSigStartValue" SG_ 1410 NrOfMappedObjects_1601_00 1;
BA_ "GenSigStartValue" SG_ 1410 mappedObj5_1600_05 1631715600;
BA_ "GenSigStartValue" SG_ 1410 mappedObj4_1600_04 1631584528;
BA_ "GenSigStartValue" SG_ 1410 mappedObj3_1600_03 1631518984;
BA_ "GenSigStartValue" SG_ 1410 mappedObj2_1600_02 1631453448;
BA_ "GenSigStartValue" SG_ 1410 mappedObj1_1600_01 1630929160;
BA_ "GenSigStartValue" SG_ 1410 NrOfMappedObjects_1600_00 5;
BA_ "GenSigStartValue" SG_ 1410 TransmissionType_1402_02 255;
BA_ "GenSigStartValue" SG_ 1410 COB_ID_1402_01 2147484674;
BA_ "GenSigStartValue" SG_ 1410 NrOfEntries_1402_00 2;
BA_ "GenSigStartValue" SG_ 1410 TransmissionType_1401_02 255;
BA_ "GenSigStartValue" SG_ 1410 COB_ID_1401_01 661;
BA_ "GenSigStartValue" SG_ 1410 NrOfEntries_1401_00 2;
BA_ "GenSigStartValue" SG_ 1410 TransmissionType_1400_02 255;
BA_ "GenSigStartValue" SG_ 1410 COB_ID_1400_01 1153;
BA_ "GenSigStartValue" SG_ 1410 NrOfEntries_1400_00 2;
BA_ "GenSigStartValue" SG_ 1410 Vendor_Id_1018_01 5;
BA_ "GenSigStartValue" SG_ 1410 NrOfElements_1018_00 1;
BA_ "GenSigStartValue" SG_ 1410 Sync_Window_Length_1007 100;
BA_ "GenSigStartValue" SG_ 1410 Communication_Cycle_Period_1006 200000;
BA_ "GenSigStartValue" SG_ 1410 COB_ID_SYNC_1005 2147483776;
BA_ "GenSigStartValue" SG_ 1410 Device_Type_1000 413;
BA_ "GenSigStartValue" SG_ 1410 Index 4096;
BA_ "SystemSignalLongSymbol" SG_ 1538 requested_engine_speed_mini_0000 "requested_engine_speed_minimum_value_range_614A_03";
BA_ "GenSigStartValue" SG_ 1538 requested_engine_speed_maxi_0000 64255;
BA_ "SystemSignalLongSymbol" SG_ 1538 requested_engine_speed_maxi_0000 "requested_engine_speed_maximum_value_range_614A_02";
BA_ "SystemSignalLongSymbol" SG_ 1538 requested_engine_speed_valu_0001 "requested_engine_speed_value_614A_01";
BA_ "GenSigStartValue" SG_ 1538 requested_engine_speed_numb_0000 3;
BA_ "SystemSignalLongSymbol" SG_ 1538 requested_engine_speed_numb_0000 "requested_engine_speed_number_of_entries_614A_00";
BA_ "SystemSignalLongSymbol" SG_ 1538 requested_engine_speed_lowe_0005 "requested_engine_speed_lower_limit_minimum_value_range_6142_03";
BA_ "GenSigStartValue" SG_ 1538 requested_engine_speed_lowe_0006 64255;
BA_ "SystemSignalLongSymbol" SG_ 1538 requested_engine_speed_lowe_0006 "requested_engine_speed_lower_limit_maximum_value_range_6142_02";
BA_ "GenSigStartValue" SG_ 1538 requested_engine_speed_lowe_0007 65535;
BA_ "SystemSignalLongSymbol" SG_ 1538 requested_engine_speed_lowe_0007 "requested_engine_speed_lower_limit_value_6142_01";
BA_ "GenSigStartValue" SG_ 1538 requested_engine_speed_lowe_0008 3;
BA_ "SystemSignalLongSymbol" SG_ 1538 requested_engine_speed_lowe_0008 "requested_engine_speed_lower_limit_number_of_entries_6142_00";
BA_ "SystemSignalLongSymbol" SG_ 1538 requested_engine_speed_uppe_0005 "requested_engine_speed_upper_limit_minimum_value_range_6140_03";
BA_ "GenSigStartValue" SG_ 1538 requested_engine_speed_uppe_0006 64255;
BA_ "SystemSignalLongSymbol" SG_ 1538 requested_engine_speed_uppe_0006 "requested_engine_speed_upper_limit_maximum_value_range_6140_02";
BA_ "GenSigStartValue" SG_ 1538 requested_engine_speed_uppe_0007 65535;
BA_ "SystemSignalLongSymbol" SG_ 1538 requested_engine_speed_uppe_0007 "requested_engine_speed_upper_limit_value_6140_01";
BA_ "GenSigStartValue" SG_ 1538 requested_engine_speed_uppe_0008 3;
BA_ "SystemSignalLongSymbol" SG_ 1538 requested_engine_speed_uppe_0008 "requested_engine_speed_upper_limit_number_of_entries_6140_00";
BA_ "GenSigStartValue" SG_ 1538 engine_stop_switch_Bit_1_613F_01 1;
BA_ "GenSigStartValue" SG_ 1538 engine_stop_switch_Number_o_0000 1;
BA_ "SystemSignalLongSymbol" SG_ 1538 engine_stop_switch_Number_o_0000 "engine_stop_switch_Number_of_entries_613F_00";
BA_ "GenSigStartValue" SG_ 1538 engine_start_switch_Bit_1_6_0000 1;
BA_ "SystemSignalLongSymbol" SG_ 1538 engine_start_switch_Bit_1_6_0000 "engine_start_switch_Bit_1_613E_01";
BA_ "GenSigStartValue" SG_ 1538 engine_start_switch_Number__0000 1;
BA_ "SystemSignalLongSymbol" SG_ 1538 engine_start_switch_Number__0000 "engine_start_switch_Number_of_entries_613E_00";
BA_ "SystemSignalLongSymbol" SG_ 1538 first_clutch_dependent_PTO__0003 "first_clutch_dependent_PTO_switch_Bit_1_6136_01";
BA_ "GenSigStartValue" SG_ 1538 first_clutch_dependent_PTO__0004 1;
BA_ "SystemSignalLongSymbol" SG_ 1538 first_clutch_dependent_PTO__0004 "first_clutch_dependent_PTO_switch_Number_of_entries_6136_00";
BA_ "SystemSignalLongSymbol" SG_ 1538 first_engine_mounted_PTO_fe_0003 "first_engine_mounted_PTO_feedback_Bit_1_6131_01";
BA_ "GenSigStartValue" SG_ 1538 first_engine_mounted_PTO_fe_0004 1;
BA_ "SystemSignalLongSymbol" SG_ 1538 first_engine_mounted_PTO_fe_0004 "first_engine_mounted_PTO_feedback_Number_of_entries_6131_00";
BA_ "SystemSignalLongSymbol" SG_ 1538 engine_speed_minimum_value__0000 "engine_speed_minimum_value_range_6113_03";
BA_ "GenSigStartValue" SG_ 1538 engine_speed_maximum_value__0000 64255;
BA_ "SystemSignalLongSymbol" SG_ 1538 engine_speed_maximum_value__0000 "engine_speed_maximum_value_range_6113_02";
BA_ "GenSigStartValue" SG_ 1538 EngineSpeed_6113_01 65535;
BA_ "GenSigStartValue" SG_ 1538 NrOfObjects_6113_00 3;
BA_ "GenSigStartValue" SG_ 1538 current_gear_minimum_value__0000 4294967171;
BA_ "SystemSignalLongSymbol" SG_ 1538 current_gear_minimum_value__0000 "current_gear_minimum_value_range_610C_03";
BA_ "GenSigStartValue" SG_ 1538 current_gear_maximum_value__0000 125;
BA_ "SystemSignalLongSymbol" SG_ 1538 current_gear_maximum_value__0000 "current_gear_maximum_value_range_610C_02";
BA_ "GenSigStartValue" SG_ 1538 NrOfObjects_610C_00 3;
BA_ "SystemSignalLongSymbol" SG_ 1538 wheel_based_vehicle_speed_m_0000 "wheel_based_vehicle_speed_minimum_value_range_6006_03";
BA_ "GenSigStartValue" SG_ 1538 wheel_based_vehicle_speed_m_0001 64000;
BA_ "SystemSignalLongSymbol" SG_ 1538 wheel_based_vehicle_speed_m_0001 "wheel_based_vehicle_speed_maximum_value_range_6006_02";
BA_ "GenSigStartValue" SG_ 1538 wheel_based_vehicle_speed_v_0002 65535;
BA_ "SystemSignalLongSymbol" SG_ 1538 wheel_based_vehicle_speed_v_0002 "wheel_based_vehicle_speed_value_6006_01";
BA_ "GenSigStartValue" SG_ 1538 wheel_based_vehicle_speed_n_0000 3;
BA_ "SystemSignalLongSymbol" SG_ 1538 wheel_based_vehicle_speed_n_0000 "wheel_based_vehicle_speed_number_of_entries_6006_00";
BA_ "SystemSignalLongSymbol" SG_ 1538 park_brake_demand_value_min_0000 "park_brake_demand_value_minimum_value_range_6000_03";
BA_ "GenSigStartValue" SG_ 1538 park_brake_demand_value_max_0000 250;
BA_ "SystemSignalLongSymbol" SG_ 1538 park_brake_demand_value_max_0000 "park_brake_demand_value_maximum_value_range_6000_02";
BA_ "GenSigStartValue" SG_ 1538 NrOfObjects_6000_00 3;
BA_ "GenSigStartValue" SG_ 1538 mappedObj5_1A00_05 1628635408;
BA_ "GenSigStartValue" SG_ 1538 mappedObj4_1A00_04 1611006224;
BA_ "GenSigStartValue" SG_ 1538 mappedObj3_1A00_03 1630601480;
BA_ "GenSigStartValue" SG_ 1538 mappedObj2_1A00_02 1610613000;
BA_ "GenSigStartValue" SG_ 1538 mappedObj1_1A00_01 1628176648;
BA_ "GenSigStartValue" SG_ 1538 NrOfMappedObjects_1A00_00 5;
BA_ "GenSigStartValue" SG_ 1538 TransmissionType_1802_02 255;
BA_ "GenSigStartValue" SG_ 1538 COB_ID_1802_01 2147484546;
BA_ "GenSigStartValue" SG_ 1538 NrOfEntries_1802_00 5;
BA_ "GenSigStartValue" SG_ 1538 TransmissionType_1801_02 255;
BA_ "GenSigStartValue" SG_ 1538 COB_ID_1801_01 2147484290;
BA_ "GenSigStartValue" SG_ 1538 NrOfEntries_1801_00 5;
BA_ "GenSigStartValue" SG_ 1538 TransmissionType_1800_02 255;
BA_ "GenSigStartValue" SG_ 1538 COB_ID_1800_01 662;
BA_ "GenSigStartValue" SG_ 1538 NrOfEntries_1800_00 5;
BA_ "GenSigStartValue" SG_ 1538 mappedObj1_1601_01 1632239888;
BA_ "GenSigStartValue" SG_ 1538 NrOfMappedObjects_1601_00 1;
BA_ "GenSigStartValue" SG_ 1538 mappedObj5_1600_05 1631715600;
BA_ "GenSigStartValue" SG_ 1538 mappedObj4_1600_04 1631584528;
BA_ "GenSigStartValue" SG_ 1538 mappedObj3_1600_03 1631518984;
BA_ "GenSigStartValue" SG_ 1538 mappedObj2_1600_02 1631453448;
BA_ "GenSigStartValue" SG_ 1538 mappedObj1_1600_01 1630929160;
BA_ "GenSigStartValue" SG_ 1538 NrOfMappedObjects_1600_00 5;
BA_ "GenSigStartValue" SG_ 1538 TransmissionType_1402_02 255;
BA_ "GenSigStartValue" SG_ 1538 COB_ID_1402_01 2147484674;
BA_ "GenSigStartValue" SG_ 1538 NrOfEntries_1402_00 2;
BA_ "GenSigStartValue" SG_ 1538 TransmissionType_1401_02 255;
BA_ "GenSigStartValue" SG_ 1538 COB_ID_1401_01 661;
BA_ "GenSigStartValue" SG_ 1538 NrOfEntries_1401_00 2;
BA_ "GenSigStartValue" SG_ 1538 TransmissionType_1400_02 255;
BA_ "GenSigStartValue" SG_ 1538 COB_ID_1400_01 1153;
BA_ "GenSigStartValue" SG_ 1538 NrOfEntries_1400_00 2;
BA_ "GenSigStartValue" SG_ 1538 Vendor_Id_1018_01 5;
BA_ "GenSigStartValue" SG_ 1538 NrOfElements_1018_00 1;
BA_ "GenSigStartValue" SG_ 1538 Sync_Window_Length_1007 100;
BA_ "GenSigStartValue" SG_ 1538 Communication_Cycle_Period_1006 200000;
BA_ "GenSigStartValue" SG_ 1538 COB_ID_SYNC_1005 2147483776;
BA_ "GenSigStartValue" SG_ 1538 Device_Type_1000 413;
BA_ "GenSigStartValue" SG_ 1538 Index 4096;
BA_ "SystemSignalLongSymbol" SG_ 1153 requested_engine_speed_lowe_0009 "requested_engine_speed_lower_limit_value";
BA_ "SystemSignalLongSymbol" SG_ 1153 requested_engine_speed_uppe_0009 "requested_engine_speed_upper_limit_value";
BA_ "SystemSignalLongSymbol" SG_ 1153 first_clutch_dependent_PTO__0005 "first_clutch_dependent_PTO_switch_Bit_1";
BA_ "SystemSignalLongSymbol" SG_ 662 first_engine_mounted_PTO_fe_0005 "first_engine_mounted_PTO_feedback_Bit_1";
VAL_ 1410 SubIndex_614A 3 "requested_engine_speed_minimum_value_range" 2 "requested_engine_speed_maximum_value_range" 1 "requested_engine_speed_value" 0 "requested_engine_speed_number_of_entries" ;
VAL_ 1410 SubIndex_6142 3 "requested_engine_speed_lower_limit_minimum_value_range" 2 "requested_engine_speed_lower_limit_maximum_value_range" 1 "requested_engine_speed_lower_limit_value" 0 "requested_engine_speed_lower_limit_number_of_entries" ;
VAL_ 1410 SubIndex_6140 3 "requested_engine_speed_upper_limit_minimum_value_range" 2 "requested_engine_speed_upper_limit_maximum_value_range" 1 "requested_engine_speed_upper_limit_value" 0 "requested_engine_speed_upper_limit_number_of_entries" ;
VAL_ 1410 SubIndex_613F 1 "engine_stop_switch_Bit_1" 0 "engine_stop_switch_Number_of_entries" ;
VAL_ 1410 SubIndex_613E 1 "engine_start_switch_Bit_1" 0 "engine_start_switch_Number_of_entries" ;
VAL_ 1410 SubIndex_6136 1 "first_clutch_dependent_PTO_switch_Bit_1" 0 "first_clutch_dependent_PTO_switch_Number_of_entries" ;
VAL_ 1410 SubIndex_6131 1 "first_engine_mounted_PTO_feedback_Bit_1" 0 "first_engine_mounted_PTO_feedback_Number_of_entries" ;
VAL_ 1410 SubIndex_6113 3 "engine_speed_minimum_value_range" 2 "engine_speed_maximum_value_range" 1 "EngineSpeed" 0 "NrOfObjects" ;
VAL_ 1410 SubIndex_610C 3 "current_gear_minimum_value_range" 2 "current_gear_maximum_value_range" 1 "CurrentGearValue" 0 "NrOfObjects" ;
VAL_ 1410 SubIndex_6006 3 "wheel_based_vehicle_speed_minimum_value_range" 2 "wheel_based_vehicle_speed_maximum_value_range" 1 "wheel_based_vehicle_speed_value" 0 "wheel_based_vehicle_speed_number_of_entries" ;
VAL_ 1410 SubIndex_6000 3 "park_brake_demand_value_minimum_value_range" 2 "park_brake_demand_value_maximum_value_range" 1 "ParkBrakeDemandValue" 0 "NrOfObjects" ;
VAL_ 1410 SubIndex_1A02 0 "NrOfMappedObjects" ;
VAL_ 1410 SubIndex_1A01 0 "NrOfMappedObjects" ;
VAL_ 1410 SubIndex_1A00 5 "mappedObj5" 4 "mappedObj4" 3 "mappedObj3" 2 "mappedObj2" 1 "mappedObj1" 0 "NrOfMappedObjects" ;
VAL_ 1410 SubIndex_1802 5 "EventTimer" 2 "TransmissionType" 1 "COB-ID" 0 "NrOfEntries" ;
VAL_ 1410 SubIndex_1801 5 "EventTimer" 2 "TransmissionType" 1 "COB-ID" 0 "NrOfEntries" ;
VAL_ 1410 SubIndex_1800 5 "EventTimer" 2 "TransmissionType" 1 "COB-ID" 0 "NrOfEntries" ;
VAL_ 1410 SubIndex_1602 0 "NrOfMappedObjects" ;
VAL_ 1410 SubIndex_1601 1 "mappedObj1" 0 "NrOfMappedObjects" ;
VAL_ 1410 SubIndex_1600 5 "mappedObj5" 4 "mappedObj4" 3 "mappedObj3" 2 "mappedObj2" 1 "mappedObj1" 0 "NrOfMappedObjects" ;
VAL_ 1410 SubIndex_1402 2 "TransmissionType" 1 "COB-ID" 0 "NrOfEntries" ;
VAL_ 1410 SubIndex_1401 2 "TransmissionType" 1 "COB-ID" 0 "NrOfEntries" ;
VAL_ 1410 SubIndex_1400 2 "TransmissionType" 1 "COB-ID" 0 "NrOfEntries" ;
VAL_ 1410 SubIndex_1018 1 "Vendor Id" 0 "NrOfElements" ;
VAL_ 1410 SubIndex_1007 0 "Sync_Window Length" ;
VAL_ 1410 SubIndex_1006 0 "Communication Cycle Period" ;
VAL_ 1410 SubIndex_1005 0 "COB-ID SYNC" ;
VAL_ 1410 SubIndex_1001 0 "ErrorRegister" ;
VAL_ 1410 SubIndex_1000 0 "Device Type" ;
VAL_ 1410 Index 24906 "ReqEngSpeed" 24898 "ReqEngSpeedLowerLimit" 24896 "ReqEngSpeedUpperLimit" 24895 "engine_stop_switch" 24894 "EngineStartSwitch" 24886 "ClutchPTOSwitch" 24881 "PTOFeedBack" 24851 "EngineSpeed" 24844 "CurrentGear" 24582 "wheel_based_vehicle_speed" 24576 "ParkBrakeDemandValue" 6658 "TxPDOMapping" 6657 "TxPDOMapping" 6656 "TxPDOMapping" 6146 "TxPDOComPar" 6145 "TxPDOComPar" 6144 "TxPDOComPar" 5634 "RxPDOMapping" 5633 "RxPDOMapping" 5632 "RxPDOMapping" 5122 "RxPDOComPar" 5121 "RxPDOComPar" 5120 "RxPDOComPar" 4120 "Identity Object" 4103 "Sync_Window Length" 4102 "Communication Cycle Period" 4101 "COB-ID SYNC" 4097 "ErrorRegister" 4096 "Device Type" ;
VAL_ 1410 TransferType 1 "Expedited transfer" 0 "Normal transfer" ;
VAL_ 1410 SizeIndicator 1 "Size is indicated" 0 "Size is not indicated" ;
VAL_ 1410 SCS 2 "Upload" 1 "Download" ;
VAL_ 1538 SubIndex_614A 3 "requested_engine_speed_minimum_value_range" 2 "requested_engine_speed_maximum_value_range" 1 "requested_engine_speed_value" 0 "requested_engine_speed_number_of_entries" ;
VAL_ 1538 SubIndex_6142 3 "requested_engine_speed_lower_limit_minimum_value_range" 2 "requested_engine_speed_lower_limit_maximum_value_range" 1 "requested_engine_speed_lower_limit_value" 0 "requested_engine_speed_lower_limit_number_of_entries" ;
VAL_ 1538 SubIndex_6140 3 "requested_engine_speed_upper_limit_minimum_value_range" 2 "requested_engine_speed_upper_limit_maximum_value_range" 1 "requested_engine_speed_upper_limit_value" 0 "requested_engine_speed_upper_limit_number_of_entries" ;
VAL_ 1538 SubIndex_613F 1 "engine_stop_switch_Bit_1" 0 "engine_stop_switch_Number_of_entries" ;
VAL_ 1538 SubIndex_613E 1 "engine_start_switch_Bit_1" 0 "engine_start_switch_Number_of_entries" ;
VAL_ 1538 SubIndex_6136 1 "first_clutch_dependent_PTO_switch_Bit_1" 0 "first_clutch_dependent_PTO_switch_Number_of_entries" ;
VAL_ 1538 SubIndex_6131 1 "first_engine_mounted_PTO_feedback_Bit_1" 0 "first_engine_mounted_PTO_feedback_Number_of_entries" ;
VAL_ 1538 SubIndex_6113 3 "engine_speed_minimum_value_range" 2 "engine_speed_maximum_value_range" 1 "EngineSpeed" 0 "NrOfObjects" ;
VAL_ 1538 SubIndex_610C 3 "current_gear_minimum_value_range" 2 "current_gear_maximum_value_range" 1 "CurrentGearValue" 0 "NrOfObjects" ;
VAL_ 1538 SubIndex_6006 3 "wheel_based_vehicle_speed_minimum_value_range" 2 "wheel_based_vehicle_speed_maximum_value_range" 1 "wheel_based_vehicle_speed_value" 0 "wheel_based_vehicle_speed_number_of_entries" ;
VAL_ 1538 SubIndex_6000 3 "park_brake_demand_value_minimum_value_range" 2 "park_brake_demand_value_maximum_value_range" 1 "ParkBrakeDemandValue" 0 "NrOfObjects" ;
VAL_ 1538 SubIndex_1A02 0 "NrOfMappedObjects" ;
VAL_ 1538 SubIndex_1A01 0 "NrOfMappedObjects" ;
VAL_ 1538 SubIndex_1A00 5 "mappedObj5" 4 "mappedObj4" 3 "mappedObj3" 2 "mappedObj2" 1 "mappedObj1" 0 "NrOfMappedObjects" ;
VAL_ 1538 SubIndex_1802 5 "EventTimer" 2 "TransmissionType" 1 "COB-ID" 0 "NrOfEntries" ;
VAL_ 1538 SubIndex_1801 5 "EventTimer" 2 "TransmissionType" 1 "COB-ID" 0 "NrOfEntries" ;
VAL_ 1538 SubIndex_1800 5 "EventTimer" 2 "TransmissionType" 1 "COB-ID" 0 "NrOfEntries" ;
VAL_ 1538 SubIndex_1602 0 "NrOfMappedObjects" ;
VAL_ 1538 SubIndex_1601 1 "mappedObj1" 0 "NrOfMappedObjects" ;
VAL_ 1538 SubIndex_1600 5 "mappedObj5" 4 "mappedObj4" 3 "mappedObj3" 2 "mappedObj2" 1 "mappedObj1" 0 "NrOfMappedObjects" ;
VAL_ 1538 SubIndex_1402 2 "TransmissionType" 1 "COB-ID" 0 "NrOfEntries" ;
VAL_ 1538 SubIndex_1401 2 "TransmissionType" 1 "COB-ID" 0 "NrOfEntries" ;
VAL_ 1538 SubIndex_1400 2 "TransmissionType" 1 "COB-ID" 0 "NrOfEntries" ;
VAL_ 1538 SubIndex_1018 1 "Vendor Id" 0 "NrOfElements" ;
VAL_ 1538 SubIndex_1007 0 "Sync_Window Length" ;
VAL_ 1538 SubIndex_1006 0 "Communication Cycle Period" ;
VAL_ 1538 SubIndex_1005 0 "COB-ID SYNC" ;
VAL_ 1538 SubIndex_1001 0 "ErrorRegister" ;
VAL_ 1538 SubIndex_1000 0 "Device Type" ;
VAL_ 1538 Index 24906 "ReqEngSpeed" 24898 "ReqEngSpeedLowerLimit" 24896 "ReqEngSpeedUpperLimit" 24895 "engine_stop_switch" 24894 "EngineStartSwitch" 24886 "ClutchPTOSwitch" 24881 "PTOFeedBack" 24851 "EngineSpeed" 24844 "CurrentGear" 24582 "wheel_based_vehicle_speed" 24576 "ParkBrakeDemandValue" 6658 "TxPDOMapping" 6657 "TxPDOMapping" 6656 "TxPDOMapping" 6146 "TxPDOComPar" 6145 "TxPDOComPar" 6144 "TxPDOComPar" 5634 "RxPDOMapping" 5633 "RxPDOMapping" 5632 "RxPDOMapping" 5122 "RxPDOComPar" 5121 "RxPDOComPar" 5120 "RxPDOComPar" 4120 "Identity Object" 4103 "Sync_Window Length" 4102 "Communication Cycle Period" 4101 "COB-ID SYNC" 4097 "ErrorRegister" 4096 "Device Type" ;
VAL_ 1538 TransferType 1 "Expedited transfer" 0 "Normal transfer" ;
VAL_ 1538 SizeIndicator 1 "Size is indicated" 0 "Size is not indicated" ;
VAL_ 1538 CCS 2 "Upload" 1 "Download" ;
VAL_ 130 ErrorCode 65530 "(DS-413) Time out of IVN ECU with Source Address 250" 65529 "(DS-413) Time out of IVN ECU with Source Address 249" 65528 "(DS-413) Time out of IVN ECU with Source Address 248" 65527 "(DS-413) Time out of IVN ECU with Source Address 247" 65526 "(DS-413) Time out of IVN ECU with Source Address 246" 65525 "(DS-413) Time out of IVN ECU with Source Address 245" 65524 "(DS-413) Time out of IVN ECU with Source Address 244" 65523 "(DS-413) Time out of IVN ECU with Source Address 243" 65522 "(DS-413) Time out of IVN ECU with Source Address 242" 65521 "(DS-413) Time out of IVN ECU with Source Address 241" 65520 "(DS-413) Time out of IVN ECU with Source Address 240" 65519 "(DS-413) Time out of IVN ECU with Source Address 239" 65518 "(DS-413) Time out of IVN ECU with Source Address 238" 65517 "(DS-413) Time out of IVN ECU with Source Address 237" 65516 "(DS-413) Time out of IVN ECU with Source Address 236" 65515 "(DS-413) Time out of IVN ECU with Source Address 235" 65514 "(DS-413) Time out of IVN ECU with Source Address 234" 65513 "(DS-413) Time out of IVN ECU with Source Address 233" 65512 "(DS-413) Time out of IVN ECU with Source Address 232" 65511 "(DS-413) Time out of IVN ECU with Source Address 231" 65510 "(DS-413) Time out of IVN ECU with Source Address 230" 65509 "(DS-413) Time out of IVN ECU with Source Address 229" 65508 "(DS-413) Time out of IVN ECU with Source Address 228" 65507 "(DS-413) Time out of IVN ECU with Source Address 227" 65506 "(DS-413) Time out of IVN ECU with Source Address 226" 65505 "(DS-413) Time out of IVN ECU with Source Address 225" 65504 "(DS-413) Time out of IVN ECU with Source Address 224" 65503 "(DS-413) Time out of IVN ECU with Source Address 223" 65502 "(DS-413) Time out of IVN ECU with Source Address 222" 65501 "(DS-413) Time out of IVN ECU with Source Address 221" 65500 "(DS-413) Time out of IVN ECU with Source Address 220" 65499 "(DS-413) Time out of IVN ECU with Source Address 219" 65498 "(DS-413) Time out of IVN ECU with Source Address 218" 65497 "(DS-413) Time out of IVN ECU with Source Address 217" 65496 "(DS-413) Time out of IVN ECU with Source Address 216" 65495 "(DS-413) Time out of IVN ECU with Source Address 215" 65494 "(DS-413) Time out of IVN ECU with Source Address 214" 65493 "(DS-413) Time out of IVN ECU with Source Address 213" 65492 "(DS-413) Time out of IVN ECU with Source Address 212" 65491 "(DS-413) Time out of IVN ECU with Source Address 211" 65490 "(DS-413) Time out of IVN ECU with Source Address 210" 65489 "(DS-413) Time out of IVN ECU with Source Address 209" 65488 "(DS-413) Time out of IVN ECU with Source Address 208" 65487 "(DS-413) Time out of IVN ECU with Source Address 207" 65486 "(DS-413) Time out of IVN ECU with Source Address 206" 65485 "(DS-413) Time out of IVN ECU with Source Address 205" 65484 "(DS-413) Time out of IVN ECU with Source Address 204" 65483 "(DS-413) Time out of IVN ECU with Source Address 203" 65482 "(DS-413) Time out of IVN ECU with Source Address 202" 65481 "(DS-413) Time out of IVN ECU with Source Address 201" 65480 "(DS-413) Time out of IVN ECU with Source Address 200" 65479 "(DS-413) Time out of IVN ECU with Source Address 199" 65478 "(DS-413) Time out of IVN ECU with Source Address 198" 65477 "(DS-413) Time out of IVN ECU with Source Address 197" 65476 "(DS-413) Time out of IVN ECU with Source Address 196" 65475 "(DS-413) Time out of IVN ECU with Source Address 195" 65474 "(DS-413) Time out of IVN ECU with Source Address 194" 65473 "(DS-413) Time out of IVN ECU with Source Address 193" 65472 "(DS-413) Time out of IVN ECU with Source Address 192" 65471 "(DS-413) Time out of IVN ECU with Source Address 191" 65470 "(DS-413) Time out of IVN ECU with Source Address 190" 65469 "(DS-413) Time out of IVN ECU with Source Address 189" 65468 "(DS-413) Time out of IVN ECU with Source Address 188" 65467 "(DS-413) Time out of IVN ECU with Source Address 187" 65466 "(DS-413) Time out of IVN ECU with Source Address 186" 65465 "(DS-413) Time out of IVN ECU with Source Address 185" 65464 "(DS-413) Time out of IVN ECU with Source Address 184" 65463 "(DS-413) Time out of IVN ECU with Source Address 183" 65462 "(DS-413) Time out of IVN ECU with Source Address 182" 65461 "(DS-413) Time out of IVN ECU with Source Address 181" 65460 "(DS-413) Time out of IVN ECU with Source Address 180" 65459 "(DS-413) Time out of IVN ECU with Source Address 179" 65458 "(DS-413) Time out of IVN ECU with Source Address 178" 65457 "(DS-413) Time out of IVN ECU with Source Address 177" 65456 "(DS-413) Time out of IVN ECU with Source Address 176" 65455 "(DS-413) Time out of IVN ECU with Source Address 175" 65454 "(DS-413) Time out of IVN ECU with Source Address 174" 65453 "(DS-413) Time out of IVN ECU with Source Address 173" 65452 "(DS-413) Time out of IVN ECU with Source Address 172" 65451 "(DS-413) Time out of IVN ECU with Source Address 171" 65450 "(DS-413) Time out of IVN ECU with Source Address 170" 65449 "(DS-413) Time out of IVN ECU with Source Address 169" 65448 "(DS-413) Time out of IVN ECU with Source Address 168" 65447 "(DS-413) Time out of IVN ECU with Source Address 167" 65446 "(DS-413) Time out of IVN ECU with Source Address 166" 65445 "(DS-413) Time out of IVN ECU with Source Address 165" 65444 "(DS-413) Time out of IVN ECU with Source Address 164" 65443 "(DS-413) Time out of IVN ECU with Source Address 163" 65442 "(DS-413) Time out of IVN ECU with Source Address 162" 65441 "(DS-413) Time out of IVN ECU with Source Address 161" 65440 "(DS-413) Time out of IVN ECU with Source Address 160" 65439 "(DS-413) Time out of IVN ECU with Source Address 159" 65438 "(DS-413) Time out of IVN ECU with Source Address 158" 65437 "(DS-413) Time out of IVN ECU with Source Address 157" 65436 "(DS-413) Time out of IVN ECU with Source Address 156" 65435 "(DS-413) Time out of IVN ECU with Source Address 155" 65434 "(DS-413) Time out of IVN ECU with Source Address 154" 65433 "(DS-413) Time out of IVN ECU with Source Address 153" 65432 "(DS-413) Time out of IVN ECU with Source Address 152" 65431 "(DS-413) Time out of IVN ECU with Source Address 151" 65430 "(DS-413) Time out of IVN ECU with Source Address 150" 65429 "(DS-413) Time out of IVN ECU with Source Address 149" 65428 "(DS-413) Time out of IVN ECU with Source Address 148" 65427 "(DS-413) Time out of IVN ECU with Source Address 147" 65426 "(DS-413) Time out of IVN ECU with Source Address 146" 65425 "(DS-413) Time out of IVN ECU with Source Address 145" 65424 "(DS-413) Time out of IVN ECU with Source Address 144" 65423 "(DS-413) Time out of IVN ECU with Source Address 143" 65422 "(DS-413) Time out of IVN ECU with Source Address 142" 65421 "(DS-413) Time out of IVN ECU with Source Address 141" 65420 "(DS-413) Time out of IVN ECU with Source Address 140" 65419 "(DS-413) Time out of IVN ECU with Source Address 139" 65418 "(DS-413) Time out of IVN ECU with Source Address 138" 65417 "(DS-413) Time out of IVN ECU with Source Address 137" 65416 "(DS-413) Time out of IVN ECU with Source Address 136" 65415 "(DS-413) Time out of IVN ECU with Source Address 135" 65414 "(DS-413) Time out of IVN ECU with Source Address 134" 65413 "(DS-413) Time out of IVN ECU with Source Address 133" 65412 "(DS-413) Time out of IVN ECU with Source Address 132" 65411 "(DS-413) Time out of IVN ECU with Source Address 131" 65410 "(DS-413) Time out of IVN ECU with Source Address 130" 65409 "(DS-413) Time out of IVN ECU with Source Address 129" 65408 "(DS-413) Time out of IVN ECU with Source Address 128" 65407 "(DS-413) Time out of IVN ECU with Source Address 127" 65406 "(DS-413) Time out of IVN ECU with Source Address 126" 65405 "(DS-413) Time out of IVN ECU with Source Address 125" 65404 "(DS-413) Time out of IVN ECU with Source Address 124" 65403 "(DS-413) Time out of IVN ECU with Source Address 123" 65402 "(DS-413) Time out of IVN ECU with Source Address 122" 65401 "(DS-413) Time out of IVN ECU with Source Address 121" 65400 "(DS-413) Time out of IVN ECU with Source Address 120" 65399 "(DS-413) Time out of IVN ECU with Source Address 119" 65398 "(DS-413) Time out of IVN ECU with Source Address 118" 65397 "(DS-413) Time out of IVN ECU with Source Address 117" 65396 "(DS-413) Time out of IVN ECU with Source Address 116" 65395 "(DS-413) Time out of IVN ECU with Source Address 115" 65394 "(DS-413) Time out of IVN ECU with Source Address 114" 65393 "(DS-413) Time out of IVN ECU with Source Address 113" 65392 "(DS-413) Time out of IVN ECU with Source Address 112" 65391 "(DS-413) Time out of IVN ECU with Source Address 111" 65390 "(DS-413) Time out of IVN ECU with Source Address 110" 65389 "(DS-413) Time out of IVN ECU with Source Address 109" 65388 "(DS-413) Time out of IVN ECU with Source Address 108" 65387 "(DS-413) Time out of IVN ECU with Source Address 107" 65386 "(DS-413) Time out of IVN ECU with Source Address 106" 65385 "(DS-413) Time out of IVN ECU with Source Address 105" 65384 "(DS-413) Time out of IVN ECU with Source Address 104" 65383 "(DS-413) Time out of IVN ECU with Source Address 103" 65382 "(DS-413) Time out of IVN ECU with Source Address 102" 65381 "(DS-413) Time out of IVN ECU with Source Address 101" 65380 "(DS-413) Time out of IVN ECU with Source Address 100" 65379 "(DS-413) Time out of IVN ECU with Source Address 99" 65378 "(DS-413) Time out of IVN ECU with Source Address 98" 65377 "(DS-413) Time out of IVN ECU with Source Address 97" 65376 "(DS-413) Time out of IVN ECU with Source Address 96" 65375 "(DS-413) Time out of IVN ECU with Source Address 95" 65374 "(DS-413) Time out of IVN ECU with Source Address 94" 65373 "(DS-413) Time out of IVN ECU with Source Address 93" 65372 "(DS-413) Time out of IVN ECU with Source Address 92" 65371 "(DS-413) Time out of IVN ECU with Source Address 91" 65370 "(DS-413) Time out of IVN ECU with Source Address 90" 65369 "(DS-413) Time out of IVN ECU with Source Address 89" 65368 "(DS-413) Time out of IVN ECU with Source Address 88" 65367 "(DS-413) Time out of IVN ECU with Source Address 87" 65366 "(DS-413) Time out of IVN ECU with Source Address 86" 65365 "(DS-413) Time out of IVN ECU with Source Address 85" 65364 "(DS-413) Time out of IVN ECU with Source Address 84" 65363 "(DS-413) Time out of IVN ECU with Source Address 83" 65362 "(DS-413) Time out of IVN ECU with Source Address 82" 65361 "(DS-413) Time out of IVN ECU with Source Address 81" 65360 "(DS-413) Time out of IVN ECU with Source Address 80" 65359 "(DS-413) Time out of IVN ECU with Source Address 79" 65358 "(DS-413) Time out of IVN ECU with Source Address 78" 65357 "(DS-413) Time out of IVN ECU with Source Address 77" 65356 "(DS-413) Time out of IVN ECU with Source Address 76" 65355 "(DS-413) Time out of IVN ECU with Source Address 75" 65354 "(DS-413) Time out of IVN ECU with Source Address 74" 65353 "(DS-413) Time out of IVN ECU with Source Address 73" 65352 "(DS-413) Time out of IVN ECU with Source Address 72" 65351 "(DS-413) Time out of IVN ECU with Source Address 71" 65350 "(DS-413) Time out of IVN ECU with Source Address 70" 65349 "(DS-413) Time out of IVN ECU with Source Address 69" 65348 "(DS-413) Time out of IVN ECU with Source Address 68" 65347 "(DS-413) Time out of IVN ECU with Source Address 67" 65346 "(DS-413) Time out of IVN ECU with Source Address 66" 65345 "(DS-413) Time out of IVN ECU with Source Address 65" 65344 "(DS-413) Time out of IVN ECU with Source Address 64" 65343 "(DS-413) Time out of IVN ECU with Source Address 63" 65342 "(DS-413) Time out of IVN ECU with Source Address 62" 65341 "(DS-413) Time out of IVN ECU with Source Address 61" 65340 "(DS-413) Time out of IVN ECU with Source Address 60" 65339 "(DS-413) Time out of IVN ECU with Source Address 59" 65338 "(DS-413) Time out of IVN ECU with Source Address 58" 65337 "(DS-413) Time out of IVN ECU with Source Address 57" 65336 "(DS-413) Time out of IVN ECU with Source Address 56" 65335 "(DS-413) Time out of IVN ECU with Source Address 55" 65334 "(DS-413) Time out of IVN ECU with Source Address 54" 65333 "(DS-413) Time out of IVN ECU with Source Address 53" 65332 "(DS-413) Time out of IVN ECU with Source Address 52" 65331 "(DS-413) Time out of IVN ECU with Source Address 51" 65330 "(DS-413) Time out of IVN ECU with Source Address 50" 65329 "(DS-413) Time out of IVN ECU with Source Address 49" 65328 "(DS-413) Time out of IVN ECU with Source Address 48" 65327 "(DS-413) Time out of IVN ECU with Source Address 47" 65326 "(DS-413) Time out of IVN ECU with Source Address 46" 65325 "(DS-413) Time out of IVN ECU with Source Address 45" 65324 "(DS-413) Time out of IVN ECU with Source Address 44" 65323 "(DS-413) Time out of IVN ECU with Source Address 43" 65322 "(DS-413) Time out of IVN ECU with Source Address 42" 65321 "(DS-413) Time out of IVN ECU with Source Address 41" 65320 "(DS-413) Time out of IVN ECU with Source Address 40" 65319 "(DS-413) Time out of IVN ECU with Source Address 39" 65318 "(DS-413) Time out of IVN ECU with Source Address 38" 65317 "(DS-413) Time out of IVN ECU with Source Address 37" 65316 "(DS-413) Time out of IVN ECU with Source Address 36" 65315 "(DS-413) Time out of IVN ECU with Source Address 35" 65314 "(DS-413) Time out of IVN ECU with Source Address 34" 65313 "(DS-413) Time out of IVN ECU with Source Address 33" 65312 "(DS-413) Time out of IVN ECU with Source Address 32" 65311 "(DS-413) Time out of IVN ECU with Source Address 31" 65310 "(DS-413) Time out of IVN ECU with Source Address 30" 65309 "(DS-413) Time out of IVN ECU with Source Address 29" 65308 "(DS-413) Time out of IVN ECU with Source Address 28" 65307 "(DS-413) Time out of IVN ECU with Source Address 27" 65306 "(DS-413) Time out of IVN ECU with Source Address 26" 65305 "(DS-413) Time out of IVN ECU with Source Address 25" 65304 "(DS-413) Time out of IVN ECU with Source Address 24" 65303 "(DS-413) Time out of IVN ECU with Source Address 23" 65302 "(DS-413) Time out of IVN ECU with Source Address 22" 65301 "(DS-413) Time out of IVN ECU with Source Address 21" 65300 "(DS-413) Time out of IVN ECU with Source Address 20" 65299 "(DS-413) Time out of IVN ECU with Source Address 19" 65298 "(DS-413) Time out of IVN ECU with Source Address 18" 65297 "(DS-413) Time out of IVN ECU with Source Address 17" 65296 "(DS-413) Time out of IVN ECU with Source Address 16" 65295 "(DS-413) Time out of IVN ECU with Source Address 15" 65294 "(DS-413) Time out of IVN ECU with Source Address 14" 65293 "(DS-413) Time out of IVN ECU with Source Address 13" 65292 "(DS-413) Time out of IVN ECU with Source Address 12" 65291 "(DS-413) Time out of IVN ECU with Source Address 11" 65290 "(DS-413) Time out of IVN ECU with Source Address 10" 65289 "(DS-413) Time out of IVN ECU with Source Address 9" 65288 "(DS-413) Time out of IVN ECU with Source Address 8" 65287 "(DS-413) Time out of IVN ECU with Source Address 7" 65286 "(DS-413) Time out of IVN ECU with Source Address 6" 65285 "(DS-413) Time out of IVN ECU with Source Address 5" 65284 "(DS-413) Time out of IVN ECU with Source Address 4" 65283 "(DS-413) Time out of IVN ECU with Source Address 3" 65282 "(DS-413) Time out of IVN ECU with Source Address 2" 65281 "(DS-413) Time out of IVN ECU with Source Address 1" 33360 "RPDO timeout" 33344 "Unexpected SYNC data length" 33328 "DAM MPDO not processed, destination object not available" 33312 "PDO length exceeded" 33296 "PDO not processed due to length error" 33104 "Transmit COB-ID collision" 33088 "Recovered from bus off state" 33072 "Life guard error or heartbeat error" 33056 "CAN in error passive mode" 33040 "CAN overrun (objects lost)" ;
VAL_ 0 Node_ID 1 "Master" 11 "LadderDrive" 10 "ControlPanel" 12 "SupportFront" 13 "SupportRear" 2 "TTGateway" 0 "All" ;
VAL_ 0 CS 130 "Reset Communication" 129 "Reset Node" 128 "Enter Pre-Operational" 2 "Stop" 1 "Start" ;
VAL_ 2021 LSS_TableIndex 8 "10" 7 "20" 6 "50" 5 "100" 4 "125" 3 "250" 2 "500" 1 "800" 0 "1000" ;
VAL_ 2021 LSS_TableSelector 0 "Std_CiA_Table" ;
VAL_ 2021 LSS_Mode 1 "Configuration" 0 "Operation" ;
VAL_ 2021 LSS_M_CS 94 "InquireNodeID" 93 "InquireSerial" 92 "InquireRevision" 91 "InquireProduct" 90 "InquireVendor" 81 "FastScan" 23 "StoreConfiguration" 21 "ActivateBitTiming" 19 "ConfigureBitTiming" 17 "ConfigureNodeID" 76 "IdentifyNonConfSlave" 75 "IdentifySerialHigh" 74 "IdentifySerialLow" 73 "IdentifyRevisionHigh" 72 "IdentifyRevisionLow" 71 "IdentifyProduct" 70 "IdentifyVendor" 67 "SwitchModeSelectSerial" 66 "SwitchModeSelectRevision" 65 "SwitchModeSelectProduct" 64 "SwitchModeSelectVendor" 4 "SwitchModeGlobal" ;
VAL_ 2020 LSS_StoreCfg_ErrCode 255 "Impl_spec_error" 2 "Storage_media_access_error" 1 "Not_supported" 0 "Success" ;
VAL_ 2020 LSS_CfgBitTim_ErrCode 255 "Impl_spec_error" 1 "Not_supported" 0 "Success" ;
VAL_ 2020 LSS_CfgNodeID_ErrCode 255 "Impl_spec_error" 1 "NodeID_Out_Of_Range" 0 "Success" ;
VAL_ 2020 LSS_S_CS 94 "InquireNodeID" 93 "InquireSerial" 92 "InquireRevision" 91 "InquireProduct" 90 "InquireVendor" 76 "IdentifyNonConfSlave" 79 "IdentifySlave" 23 "StoreConfiguration" 19 "ConfigureBitTiming" 17 "ConfigureNodeID" 68 "SwitchModeSelectConfirm" ;
SG_MUL_VAL_ 1410 requested_engine_speed_minimum_v SubIndex_614A 3-3;
SG_MUL_VAL_ 1410 requested_engine_speed_maximum_v SubIndex_614A 2-2;
SG_MUL_VAL_ 1410 requested_engine_speed_value_614 SubIndex_614A 1-1;
SG_MUL_VAL_ 1410 requested_engine_speed_number_of SubIndex_614A 0-0;
SG_MUL_VAL_ 1410 SubIndex_614A Index 24906-24906;
SG_MUL_VAL_ 1410 requested_engine_speed_lowe_0001 SubIndex_6142 3-3;
SG_MUL_VAL_ 1410 requested_engine_speed_lowe_0002 SubIndex_6142 2-2;
SG_MUL_VAL_ 1410 requested_engine_speed_lowe_0003 SubIndex_6142 1-1;
SG_MUL_VAL_ 1410 requested_engine_speed_lowe_0004 SubIndex_6142 0-0;
SG_MUL_VAL_ 1410 SubIndex_6142 Index 24898-24898;
SG_MUL_VAL_ 1410 requested_engine_speed_uppe_0001 SubIndex_6140 3-3;
SG_MUL_VAL_ 1410 requested_engine_speed_uppe_0002 SubIndex_6140 2-2;
SG_MUL_VAL_ 1410 requested_engine_speed_uppe_0003 SubIndex_6140 1-1;
SG_MUL_VAL_ 1410 requested_engine_speed_uppe_0004 SubIndex_6140 0-0;
SG_MUL_VAL_ 1410 SubIndex_6140 Index 24896-24896;
SG_MUL_VAL_ 1410 engine_stop_switch_Bit_1_613F_01 SubIndex_613F 1-1;
SG_MUL_VAL_ 1410 engine_stop_switch_Number_of_ent SubIndex_613F 0-0;
SG_MUL_VAL_ 1410 SubIndex_613F Index 24895-24895;
SG_MUL_VAL_ 1410 engine_start_switch_Bit_1_613E_0 SubIndex_613E 1-1;
SG_MUL_VAL_ 1410 engine_start_switch_Number_of_en SubIndex_613E 0-0;
SG_MUL_VAL_ 1410 SubIndex_613E Index 24894-24894;
SG_MUL_VAL_ 1410 first_clutch_dependent_PTO__0001 SubIndex_6136 1-1;
SG_MUL_VAL_ 1410 first_clutch_dependent_PTO__0002 SubIndex_6136 0-0;
SG_MUL_VAL_ 1410 SubIndex_6136 Index 24886-24886;
SG_MUL_VAL_ 1410 first_engine_mounted_PTO_fe_0001 SubIndex_6131 1-1;
SG_MUL_VAL_ 1410 first_engine_mounted_PTO_fe_0002 SubIndex_6131 0-0;
SG_MUL_VAL_ 1410 SubIndex_6131 Index 24881-24881;
SG_MUL_VAL_ 1410 engine_speed_minimum_value_range SubIndex_6113 3-3;
SG_MUL_VAL_ 1410 engine_speed_maximum_value_range SubIndex_6113 2-2;
SG_MUL_VAL_ 1410 EngineSpeed_6113_01 SubIndex_6113 1-1;
SG_MUL_VAL_ 1410 NrOfObjects_6113_00 SubIndex_6113 0-0;
SG_MUL_VAL_ 1410 SubIndex_6113 Index 24851-24851;
SG_MUL_VAL_ 1410 current_gear_minimum_value_range SubIndex_610C 3-3;
SG_MUL_VAL_ 1410 current_gear_maximum_value_range SubIndex_610C 2-2;
SG_MUL_VAL_ 1410 CurrentGearValue_610C_01 SubIndex_610C 1-1;
SG_MUL_VAL_ 1410 NrOfObjects_610C_00 SubIndex_610C 0-0;
SG_MUL_VAL_ 1410 SubIndex_610C Index 24844-24844;
SG_MUL_VAL_ 1410 wheel_based_vehicle_speed_minimu SubIndex_6006 3-3;
SG_MUL_VAL_ 1410 wheel_based_vehicle_speed_maximu SubIndex_6006 2-2;
SG_MUL_VAL_ 1410 wheel_based_vehicle_speed_v_0001 SubIndex_6006 1-1;
SG_MUL_VAL_ 1410 wheel_based_vehicle_speed_number SubIndex_6006 0-0;
SG_MUL_VAL_ 1410 SubIndex_6006 Index 24582-24582;
SG_MUL_VAL_ 1410 park_brake_demand_value_minimum_ SubIndex_6000 3-3;
SG_MUL_VAL_ 1410 park_brake_demand_value_maximum_ SubIndex_6000 2-2;
SG_MUL_VAL_ 1410 ParkBrakeDemandValue_6000_01 SubIndex_6000 1-1;
SG_MUL_VAL_ 1410 NrOfObjects_6000_00 SubIndex_6000 0-0;
SG_MUL_VAL_ 1410 SubIndex_6000 Index 24576-24576;
SG_MUL_VAL_ 1410 NrOfMappedObjects_1A02_00 SubIndex_1A02 0-0;
SG_MUL_VAL_ 1410 SubIndex_1A02 Index 6658-6658;
SG_MUL_VAL_ 1410 NrOfMappedObjects_1A01_00 SubIndex_1A01 0-0;
SG_MUL_VAL_ 1410 SubIndex_1A01 Index 6657-6657;
SG_MUL_VAL_ 1410 mappedObj5_1A00_05 SubIndex_1A00 5-5;
SG_MUL_VAL_ 1410 mappedObj4_1A00_04 SubIndex_1A00 4-4;
SG_MUL_VAL_ 1410 mappedObj3_1A00_03 SubIndex_1A00 3-3;
SG_MUL_VAL_ 1410 mappedObj2_1A00_02 SubIndex_1A00 2-2;
SG_MUL_VAL_ 1410 mappedObj1_1A00_01 SubIndex_1A00 1-1;
SG_MUL_VAL_ 1410 NrOfMappedObjects_1A00_00 SubIndex_1A00 0-0;
SG_MUL_VAL_ 1410 SubIndex_1A00 Index 6656-6656;
SG_MUL_VAL_ 1410 EventTimer_1802_05 SubIndex_1802 5-5;
SG_MUL_VAL_ 1410 TransmissionType_1802_02 SubIndex_1802 2-2;
SG_MUL_VAL_ 1410 COB_ID_1802_01 SubIndex_1802 1-1;
SG_MUL_VAL_ 1410 NrOfEntries_1802_00 SubIndex_1802 0-0;
SG_MUL_VAL_ 1410 SubIndex_1802 Index 6146-6146;
SG_MUL_VAL_ 1410 EventTimer_1801_05 SubIndex_1801 5-5;
SG_MUL_VAL_ 1410 TransmissionType_1801_02 SubIndex_1801 2-2;
SG_MUL_VAL_ 1410 COB_ID_1801_01 SubIndex_1801 1-1;
SG_MUL_VAL_ 1410 NrOfEntries_1801_00 SubIndex_1801 0-0;
SG_MUL_VAL_ 1410 SubIndex_1801 Index 6145-6145;
SG_MUL_VAL_ 1410 EventTimer_1800_05 SubIndex_1800 5-5;
SG_MUL_VAL_ 1410 TransmissionType_1800_02 SubIndex_1800 2-2;
SG_MUL_VAL_ 1410 COB_ID_1800_01 SubIndex_1800 1-1;
SG_MUL_VAL_ 1410 NrOfEntries_1800_00 SubIndex_1800 0-0;
SG_MUL_VAL_ 1410 SubIndex_1800 Index 6144-6144;
SG_MUL_VAL_ 1410 NrOfMappedObjects_1602_00 SubIndex_1602 0-0;
SG_MUL_VAL_ 1410 SubIndex_1602 Index 5634-5634;
SG_MUL_VAL_ 1410 mappedObj1_1601_01 SubIndex_1601 1-1;
SG_MUL_VAL_ 1410 NrOfMappedObjects_1601_00 SubIndex_1601 0-0;
SG_MUL_VAL_ 1410 SubIndex_1601 Index 5633-5633;
SG_MUL_VAL_ 1410 mappedObj5_1600_05 SubIndex_1600 5-5;
SG_MUL_VAL_ 1410 mappedObj4_1600_04 SubIndex_1600 4-4;
SG_MUL_VAL_ 1410 mappedObj3_1600_03 SubIndex_1600 3-3;
SG_MUL_VAL_ 1410 mappedObj2_1600_02 SubIndex_1600 2-2;
SG_MUL_VAL_ 1410 mappedObj1_1600_01 SubIndex_1600 1-1;
SG_MUL_VAL_ 1410 NrOfMappedObjects_1600_00 SubIndex_1600 0-0;
SG_MUL_VAL_ 1410 SubIndex_1600 Index 5632-5632;
SG_MUL_VAL_ 1410 TransmissionType_1402_02 SubIndex_1402 2-2;
SG_MUL_VAL_ 1410 COB_ID_1402_01 SubIndex_1402 1-1;
SG_MUL_VAL_ 1410 NrOfEntries_1402_00 SubIndex_1402 0-0;
SG_MUL_VAL_ 1410 SubIndex_1402 Index 5122-5122;
SG_MUL_VAL_ 1410 TransmissionType_1401_02 SubIndex_1401 2-2;
SG_MUL_VAL_ 1410 COB_ID_1401_01 SubIndex_1401 1-1;
SG_MUL_VAL_ 1410 NrOfEntries_1401_00 SubIndex_1401 0-0;
SG_MUL_VAL_ 1410 SubIndex_1401 Index 5121-5121;
SG_MUL_VAL_ 1410 TransmissionType_1400_02 SubIndex_1400 2-2;
SG_MUL_VAL_ 1410 COB_ID_1400_01 SubIndex_1400 1-1;
SG_MUL_VAL_ 1410 NrOfEntries_1400_00 SubIndex_1400 0-0;
SG_MUL_VAL_ 1410 SubIndex_1400 Index 5120-5120;
SG_MUL_VAL_ 1410 Vendor_Id_1018_01 SubIndex_1018 1-1;
SG_MUL_VAL_ 1410 NrOfElements_1018_00 SubIndex_1018 0-0;
SG_MUL_VAL_ 1410 SubIndex_1018 Index 4120-4120;
SG_MUL_VAL_ 1410 Sync_Window_Length_1007 SubIndex_1007 0-0;
SG_MUL_VAL_ 1410 SubIndex_1007 Index 4103-4103;
SG_MUL_VAL_ 1410 Communication_Cycle_Period_1006 SubIndex_1006 0-0;
SG_MUL_VAL_ 1410 SubIndex_1006 Index 4102-4102;
SG_MUL_VAL_ 1410 COB_ID_SYNC_1005 SubIndex_1005 0-0;
SG_MUL_VAL_ 1410 SubIndex_1005 Index 4101-4101;
SG_MUL_VAL_ 1410 ErrorRegister_1001 SubIndex_1001 0-0;
SG_MUL_VAL_ 1410 SubIndex_1001 Index 4097-4097;
SG_MUL_VAL_ 1410 Device_Type_1000 SubIndex_1000 0-0;
SG_MUL_VAL_ 1410 SubIndex_1000 Index 4096-4096;
SG_MUL_VAL_ 1410 Index TransferType 1-1;
SG_MUL_VAL_ 1410 TransferType SCS 1-2;
SG_MUL_VAL_ 1410 NotUsedBytes SCS 1-2;
SG_MUL_VAL_ 1410 SizeIndicator SCS 1-2;
SG_MUL_VAL_ 1538 requested_engine_speed_mini_0000 SubIndex_614A 3-3;
SG_MUL_VAL_ 1538 requested_engine_speed_maxi_0000 SubIndex_614A 2-2;
SG_MUL_VAL_ 1538 requested_engine_speed_valu_0001 SubIndex_614A 1-1;
SG_MUL_VAL_ 1538 requested_engine_speed_numb_0000 SubIndex_614A 0-0;
SG_MUL_VAL_ 1538 SubIndex_614A Index 24906-24906;
SG_MUL_VAL_ 1538 requested_engine_speed_lowe_0005 SubIndex_6142 3-3;
SG_MUL_VAL_ 1538 requested_engine_speed_lowe_0006 SubIndex_6142 2-2;
SG_MUL_VAL_ 1538 requested_engine_speed_lowe_0007 SubIndex_6142 1-1;
SG_MUL_VAL_ 1538 requested_engine_speed_lowe_0008 SubIndex_6142 0-0;
SG_MUL_VAL_ 1538 SubIndex_6142 Index 24898-24898;
SG_MUL_VAL_ 1538 requested_engine_speed_uppe_0005 SubIndex_6140 3-3;
SG_MUL_VAL_ 1538 requested_engine_speed_uppe_0006 SubIndex_6140 2-2;
SG_MUL_VAL_ 1538 requested_engine_speed_uppe_0007 SubIndex_6140 1-1;
SG_MUL_VAL_ 1538 requested_engine_speed_uppe_0008 SubIndex_6140 0-0;
SG_MUL_VAL_ 1538 SubIndex_6140 Index 24896-24896;
SG_MUL_VAL_ 1538 engine_stop_switch_Bit_1_613F_01 SubIndex_613F 1-1;
SG_MUL_VAL_ 1538 engine_stop_switch_Number_o_0000 SubIndex_613F 0-0;
SG_MUL_VAL_ 1538 SubIndex_613F Index 24895-24895;
SG_MUL_VAL_ 1538 engine_start_switch_Bit_1_6_0000 SubIndex_613E 1-1;
SG_MUL_VAL_ 1538 engine_start_switch_Number__0000 SubIndex_613E 0-0;
SG_MUL_VAL_ 1538 SubIndex_613E Index 24894-24894;
SG_MUL_VAL_ 1538 first_clutch_dependent_PTO__0003 SubIndex_6136 1-1;
SG_MUL_VAL_ 1538 first_clutch_dependent_PTO__0004 SubIndex_6136 0-0;
SG_MUL_VAL_ 1538 SubIndex_6136 Index 24886-24886;
SG_MUL_VAL_ 1538 first_engine_mounted_PTO_fe_0003 SubIndex_6131 1-1;
SG_MUL_VAL_ 1538 first_engine_mounted_PTO_fe_0004 SubIndex_6131 0-0;
SG_MUL_VAL_ 1538 SubIndex_6131 Index 24881-24881;
SG_MUL_VAL_ 1538 engine_speed_minimum_value__0000 SubIndex_6113 3-3;
SG_MUL_VAL_ 1538 engine_speed_maximum_value__0000 SubIndex_6113 2-2;
SG_MUL_VAL_ 1538 EngineSpeed_6113_01 SubIndex_6113 1-1;
SG_MUL_VAL_ 1538 NrOfObjects_6113_00 SubIndex_6113 0-0;
SG_MUL_VAL_ 1538 SubIndex_6113 Index 24851-24851;
SG_MUL_VAL_ 1538 current_gear_minimum_value__0000 SubIndex_610C 3-3;
SG_MUL_VAL_ 1538 current_gear_maximum_value__0000 SubIndex_610C 2-2;
SG_MUL_VAL_ 1538 CurrentGearValue_610C_01 SubIndex_610C 1-1;
SG_MUL_VAL_ 1538 NrOfObjects_610C_00 SubIndex_610C 0-0;
SG_MUL_VAL_ 1538 SubIndex_610C Index 24844-24844;
SG_MUL_VAL_ 1538 wheel_based_vehicle_speed_m_0000 SubIndex_6006 3-3;
SG_MUL_VAL_ 1538 wheel_based_vehicle_speed_m_0001 SubIndex_6006 2-2;
SG_MUL_VAL_ 1538 wheel_based_vehicle_speed_v_0002 SubIndex_6006 1-1;
SG_MUL_VAL_ 1538 wheel_based_vehicle_speed_n_0000 SubIndex_6006 0-0;
SG_MUL_VAL_ 1538 SubIndex_6006 Index 24582-24582;
SG_MUL_VAL_ 1538 park_brake_demand_value_min_0000 SubIndex_6000 3-3;
SG_MUL_VAL_ 1538 park_brake_demand_value_max_0000 SubIndex_6000 2-2;
SG_MUL_VAL_ 1538 ParkBrakeDemandValue_6000_01 SubIndex_6000 1-1;
SG_MUL_VAL_ 1538 NrOfObjects_6000_00 SubIndex_6000 0-0;
SG_MUL_VAL_ 1538 SubIndex_6000 Index 24576-24576;
SG_MUL_VAL_ 1538 NrOfMappedObjects_1A02_00 SubIndex_1A02 0-0;
SG_MUL_VAL_ 1538 SubIndex_1A02 Index 6658-6658;
SG_MUL_VAL_ 1538 NrOfMappedObjects_1A01_00 SubIndex_1A01 0-0;
SG_MUL_VAL_ 1538 SubIndex_1A01 Index 6657-6657;
SG_MUL_VAL_ 1538 mappedObj5_1A00_05 SubIndex_1A00 5-5;
SG_MUL_VAL_ 1538 mappedObj4_1A00_04 SubIndex_1A00 4-4;
SG_MUL_VAL_ 1538 mappedObj3_1A00_03 SubIndex_1A00 3-3;
SG_MUL_VAL_ 1538 mappedObj2_1A00_02 SubIndex_1A00 2-2;
SG_MUL_VAL_ 1538 mappedObj1_1A00_01 SubIndex_1A00 1-1;
SG_MUL_VAL_ 1538 NrOfMappedObjects_1A00_00 SubIndex_1A00 0-0;
SG_MUL_VAL_ 1538 SubIndex_1A00 Index 6656-6656;
SG_MUL_VAL_ 1538 EventTimer_1802_05 SubIndex_1802 5-5;
SG_MUL_VAL_ 1538 TransmissionType_1802_02 SubIndex_1802 2-2;
SG_MUL_VAL_ 1538 COB_ID_1802_01 SubIndex_1802 1-1;
SG_MUL_VAL_ 1538 NrOfEntries_1802_00 SubIndex_1802 0-0;
SG_MUL_VAL_ 1538 SubIndex_1802 Index 6146-6146;
SG_MUL_VAL_ 1538 EventTimer_1801_05 SubIndex_1801 5-5;
SG_MUL_VAL_ 1538 TransmissionType_1801_02 SubIndex_1801 2-2;
SG_MUL_VAL_ 1538 COB_ID_1801_01 SubIndex_1801 1-1;
SG_MUL_VAL_ 1538 NrOfEntries_1801_00 SubIndex_1801 0-0;
SG_MUL_VAL_ 1538 SubIndex_1801 Index 6145-6145;
SG_MUL_VAL_ 1538 EventTimer_1800_05 SubIndex_1800 5-5;
SG_MUL_VAL_ 1538 TransmissionType_1800_02 SubIndex_1800 2-2;
SG_MUL_VAL_ 1538 COB_ID_1800_01 SubIndex_1800 1-1;
SG_MUL_VAL_ 1538 NrOfEntries_1800_00 SubIndex_1800 0-0;
SG_MUL_VAL_ 1538 SubIndex_1800 Index 6144-6144;
SG_MUL_VAL_ 1538 NrOfMappedObjects_1602_00 SubIndex_1602 0-0;
SG_MUL_VAL_ 1538 SubIndex_1602 Index 5634-5634;
SG_MUL_VAL_ 1538 mappedObj1_1601_01 SubIndex_1601 1-1;
SG_MUL_VAL_ 1538 NrOfMappedObjects_1601_00 SubIndex_1601 0-0;
SG_MUL_VAL_ 1538 SubIndex_1601 Index 5633-5633;
SG_MUL_VAL_ 1538 mappedObj5_1600_05 SubIndex_1600 5-5;
SG_MUL_VAL_ 1538 mappedObj4_1600_04 SubIndex_1600 4-4;
SG_MUL_VAL_ 1538 mappedObj3_1600_03 SubIndex_1600 3-3;
SG_MUL_VAL_ 1538 mappedObj2_1600_02 SubIndex_1600 2-2;
SG_MUL_VAL_ 1538 mappedObj1_1600_01 SubIndex_1600 1-1;
SG_MUL_VAL_ 1538 NrOfMappedObjects_1600_00 SubIndex_1600 0-0;
SG_MUL_VAL_ 1538 SubIndex_1600 Index 5632-5632;
SG_MUL_VAL_ 1538 TransmissionType_1402_02 SubIndex_1402 2-2;
SG_MUL_VAL_ 1538 COB_ID_1402_01 SubIndex_1402 1-1;
SG_MUL_VAL_ 1538 NrOfEntries_1402_00 SubIndex_1402 0-0;
SG_MUL_VAL_ 1538 SubIndex_1402 Index 5122-5122;
SG_MUL_VAL_ 1538 TransmissionType_1401_02 SubIndex_1401 2-2;
SG_MUL_VAL_ 1538 COB_ID_1401_01 SubIndex_1401 1-1;
SG_MUL_VAL_ 1538 NrOfEntries_1401_00 SubIndex_1401 0-0;
SG_MUL_VAL_ 1538 SubIndex_1401 Index 5121-5121;
SG_MUL_VAL_ 1538 TransmissionType_1400_02 SubIndex_1400 2-2;
SG_MUL_VAL_ 1538 COB_ID_1400_01 SubIndex_1400 1-1;
SG_MUL_VAL_ 1538 NrOfEntries_1400_00 SubIndex_1400 0-0;
SG_MUL_VAL_ 1538 SubIndex_1400 Index 5120-5120;
SG_MUL_VAL_ 1538 Vendor_Id_1018_01 SubIndex_1018 1-1;
SG_MUL_VAL_ 1538 NrOfElements_1018_00 SubIndex_1018 0-0;
SG_MUL_VAL_ 1538 SubIndex_1018 Index 4120-4120;
SG_MUL_VAL_ 1538 Sync_Window_Length_1007 SubIndex_1007 0-0;
SG_MUL_VAL_ 1538 SubIndex_1007 Index 4103-4103;
SG_MUL_VAL_ 1538 Communication_Cycle_Period_1006 SubIndex_1006 0-0;
SG_MUL_VAL_ 1538 SubIndex_1006 Index 4102-4102;
SG_MUL_VAL_ 1538 COB_ID_SYNC_1005 SubIndex_1005 0-0;
SG_MUL_VAL_ 1538 SubIndex_1005 Index 4101-4101;
SG_MUL_VAL_ 1538 ErrorRegister_1001 SubIndex_1001 0-0;
SG_MUL_VAL_ 1538 SubIndex_1001 Index 4097-4097;
SG_MUL_VAL_ 1538 Device_Type_1000 SubIndex_1000 0-0;
SG_MUL_VAL_ 1538 SubIndex_1000 Index 4096-4096;
SG_MUL_VAL_ 1538 Index TransferType 1-1;
SG_MUL_VAL_ 1538 TransferType CCS 1-2;
SG_MUL_VAL_ 1538 NotUsedBytes CCS 1-2;
SG_MUL_VAL_ 1538 SizeIndicator CCS 1-2;
